VERSION ""

NS_ :

BS_:

BU_: TPMS
VAL_TABLE_ FMI 31 "ConditionExists" 19 "Received network data in error" 18 "Below normal (moderately severe)" 17 "Below normal (least severe)" 16 "Above normal (moderately severe)" 15 "Above normal (least severe)" 14 "Special intstructions" 13 "Out of calibration" 12 "Bad intelligent device" 11 "Root cause not known" 10 "Abnormal rate of change" 9 "Abnormal update rate" 8 "Abnormal frequency" 7 "Mechanical system not responding" 6 "Current above normal" 5 "Current below normal" 4 "Voltage below normal" 3 "Voltage above normal" 2 "Data erratic" 1 "Below normal (most severe)" 0 "Above normal (most severe)" ;

BO_ 2566838526 CA: 9 Vector__XXX
 SG_ ArbitraryAddressCapable : 63|1@1+ (1,0) [0|1] "" Vector__XXX
 SG_ IndustryGroup : 60|3@1+ (1,0) [0|7] "" Vector__XXX
 SG_ VehicleSystemInstance : 56|4@1+ (1,0) [0|15] "" Vector__XXX
 SG_ VehicleSystem : 49|7@1+ (1,0) [0|127] "" Vector__XXX
 SG_ Function : 40|8@1+ (1,0) [0|255] "" Vector__XXX
 SG_ FunctionInstance : 35|5@1+ (1,0) [0|31] "" Vector__XXX
 SG_ ECUInstance : 32|3@1+ (1,0) [0|7] "" Vector__XXX
 SG_ ManufacturerCode : 21|11@1+ (1,0) [0|2047] "" Vector__XXX
 SG_ IdentityNumber : 0|21@1+ (1,0) [0|2097152] "" Vector__XXX
 SG_ AddressAssignment : 64|8@1+ (1,0) [0|255] "" Vector__XXX

BO_ 2561605374 TPRS: 8 Vector__XXX
 SG_ ReferenceTirePressSetting : 8|8@1+ (8,0) [0|2000] "kPa" Vector__XXX
 SG_ TireLocation : 0|8@1+ (1,0) [0|255] "" Vector__XXX

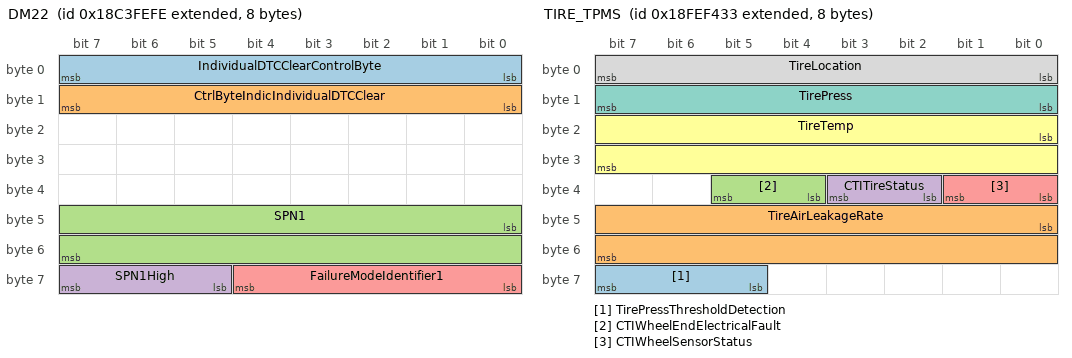
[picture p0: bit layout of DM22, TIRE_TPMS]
BO_ 2562981630 DM22: 8 Vector__XXX
 SG_ IndividualDTCClearControlByte : 0|8@1+ (1,0) [0|255] "" Vector__XXX
 SG_ CtrlByteIndicIndividualDTCClear : 8|8@1+ (1,0) [0|255] "" Vector__XXX
 SG_ SPN1 : 40|16@1+ (1,0) [0|65536] "" Vector__XXX
 SG_ SPN1High : 61|3@1+ (1,0) [0|7] "" Vector__XXX
 SG_ FailureModeIdentifier1 : 56|5@1+ (1,0) [0|0] "" Vector__XXX

BO_ 2684354558 CAPL_MSG: 1785 Vector__XXX

BO_ 2566764851 TPRI_TPMS: 8 TPMS
 SG_ ReferenceTirePress : 8|8@1+ (8,0) [0|2000] "kPa" Vector__XXX
 SG_ TireLocation : 0|8@1+ (1,0) [0|255] "" Vector__XXX

BO_ 2566845491 TIRE_TPMS: 8 TPMS
 SG_ TirePressThresholdDetection : 61|3@1+ (1,0) [0|7] "" Vector__XXX
 SG_ TireAirLeakageRate : 40|16@1+ (0.1,0) [0|6425.5] "Pa/s" Vector__XXX
 SG_ CTIWheelEndElectricalFault : 36|2@1+ (1,0) [0|3] "" Vector__XXX
 SG_ CTITireStatus : 34|2@1+ (1,0) [0|3] "" Vector__XXX
 SG_ CTIWheelSensorStatus : 32|2@1+ (1,0) [0|3] "" Vector__XXX
 SG_ TireTemp : 16|16@1+ (0.03125,-273) [-273|1735] "deg" Vector__XXX
 SG_ TirePress : 8|8@1+ (4,0) [0|1000] "kPa" Vector__XXX
 SG_ TireLocation : 0|8@1+ (1,0) [0|255] "" Vector__XXX

BO_ 2566839038 SOFT: 8 TPMS
 SG_ NmbrOfSftwrIdentificationFields : 0|8@1+ (1,0) [0|250] "steps" Vector__XXX

BO_ 2566768126 ECUID: 8 TPMS

BO_ 2566836222 DM6: 22 Vector__XXX
 SG_ SPN5 : 144|16@1+ (1,0) [0|65536] "" Vector__XXX
 SG_ SPN4 : 112|16@1+ (1,0) [0|65536] "" Vector__XXX
 SG_ SPN3 : 80|16@1+ (1,0) [0|65536] "" Vector__XXX
 SG_ SPN2 : 48|16@1+ (1,0) [0|65536] "" Vector__XXX
 SG_ FailureModeIdentifier5 : 160|5@1+ (1,0) [0|0] "" Vector__XXX
 SG_ FailureModeIdentifier4 : 128|5@1+ (1,0) [0|0] "" Vector__XXX
 SG_ FlashRedStopLamp : 12|2@1+ (1,0) [0|3] "" Vector__XXX
 SG_ FlashProtectLamp : 8|2@1+ (1,0) [0|3] "" Vector__XXX
 SG_ FlashMalfuncIndicatorLamp : 14|2@1+ (1,0) [0|3] "" Vector__XXX
 SG_ FlashAmberWarningLamp : 10|2@1+ (1,0) [0|3] "" Vector__XXX
 SG_ FailureModeIdentifier3 : 96|5@1+ (1,0) [0|0] "" Vector__XXX
 SG_ FailureModeIdentifier2 : 64|5@1+ (1,0) [0|0] "" Vector__XXX
 SG_ SPNConversionMethod5 : 175|1@1+ (1,0) [0|1] "" Vector__XXX
 SG_ SPNConversionMethod4 : 143|1@1+ (1,0) [0|1] "" Vector__XXX
 SG_ SPNConversionMethod3 : 111|1@1+ (1,0) [0|1] "" Vector__XXX
 SG_ SPNConversionMethod2 : 79|1@1+ (1,0) [0|1] "" Vector__XXX
 SG_ OccurenceCount5 : 168|7@1+ (1,0) [0|126] "" Vector__XXX
 SG_ OccurenceCount4 : 136|7@1+ (1,0) [0|126] "" Vector__XXX
 SG_ OccurenceCount3 : 104|7@1+ (1,0) [0|126] "" Vector__XXX
 SG_ OccurenceCount2 : 72|7@1+ (1,0) [0|126] "" Vector__XXX
 SG_ OccurenceCount1 : 40|7@1+ (1,0) [0|126] "" Vector__XXX
 SG_ SPNConversionMethod1 : 47|1@1+ (1,0) [0|1] "" Vector__XXX
 SG_ FailureModeIdentifier1 : 32|5@1+ (1,0) [0|0] "" Vector__XXX
 SG_ SPN1 : 16|16@1+ (1,0) [0|65536] "" Vector__XXX
 SG_ MalfunctionIndicatorLampStatus : 6|2@1+ (1,0) [0|3] "" Vector__XXX
 SG_ RedStopLampState : 4|2@1+ (1,0) [0|3] "" Vector__XXX
 SG_ AmberWarningLampStatus : 2|2@1+ (1,0) [0|3] "" Vector__XXX
 SG_ ProtectLampStatus : 0|2@1+ (1,0) [0|3] "" Vector__XXX
 SG_ SPN5High : 165|3@1+ (1,0) [0|7] "" Vector__XXX
 SG_ SPN4High : 133|3@1+ (1,0) [0|7] "" Vector__XXX
 SG_ SPN3High : 101|3@1+ (1,0) [0|7] "" Vector__XXX
 SG_ SPN2High : 69|3@1+ (1,0) [0|7] "" Vector__XXX
 SG_ SPN1High : 37|3@1+ (1,0) [0|7] "" Vector__XXX

BO_ 2566835966 DM5: 8 TPMS
 SG_ MisfireMonitoringSupport : 24|1@1+ (1,0) [0|0] "" Vector__XXX
 SG_ OBDCompliance : 16|8@1+ (1,0) [0|240] "" Vector__XXX
 SG_ PreviouslyActiveTroubleCodes : 8|8@1+ (1,0) [0|240] "" Vector__XXX
 SG_ ActiveTroubleCodes : 0|8@1+ (1,0) [0|240] "" Vector__XXX
 SG_ SecondAirSystemMonStatus : 51|1@1+ (1,0) [0|1] "" Vector__XXX
 SG_ EvaporativeSystemMonStatus : 50|1@1+ (1,0) [0|1] "" Vector__XXX
 SG_ ACSystemRefrigerantMonStatus : 52|1@1+ (1,0) [0|1] "" Vector__XXX
 SG_ OxygenSensorHeaterMonStatus : 54|1@1+ (1,0) [0|1] "" Vector__XXX
 SG_ OxygenSensorMonStatus : 53|1@1+ (1,0) [0|1] "" Vector__XXX
 SG_ EGRSystemMonitoringStatus : 55|1@1+ (1,0) [0|1] "" Vector__XXX
 SG_ CatalystMonStatus : 48|1@1+ (1,0) [0|1] "" Vector__XXX
 SG_ ColdStartAidSystemMonStatus : 56|1@1+ (1,0) [0|1] "" Vector__XXX
 SG_ HeatedCatalystMonStatus : 49|1@1+ (1,0) [0|0] "" Vector__XXX
 SG_ CatalystMonSupp : 32|1@1+ (1,0) [0|1] "" Vector__XXX
 SG_ ColdStartAidSystemMonSupp : 40|1@1+ (1,0) [0|1] "" Vector__XXX
 SG_ HeatedCatalystMonSupp : 33|1@1+ (1,0) [0|0] "" Vector__XXX
 SG_ EvaporativeSystemMonSupp : 34|1@1+ (1,0) [0|1] "" Vector__XXX
 SG_ SecondAirSystemMonSupp : 35|1@1+ (1,0) [0|1] "" Vector__XXX
 SG_ ACSystemRefrigerantMonSupp : 36|1@1+ (1,0) [0|1] "" Vector__XXX
 SG_ OxygenSensorMonSupp : 37|1@1+ (1,0) [0|1] "" Vector__XXX
 SG_ OxygenSensorHeaterMonSupp : 38|1@1+ (1,0) [0|1] "" Vector__XXX
 SG_ EGRSystemMonitoringSupp : 39|1@1+ (1,0) [0|1] "" Vector__XXX
 SG_ MisfireMonitoringStatus : 28|1@1+ (1,0) [0|0] "" Vector__XXX
 SG_ ComprehensiveCompMonStatus : 30|1@1+ (1,0) [0|1] "" Vector__XXX
 SG_ FuelSystemMonitoringStatus : 29|1@1+ (1,0) [0|1] "" Vector__XXX
 SG_ ComprehensiveComponentMonSupp : 26|1@1+ (1,0) [0|0] "" Vector__XXX
 SG_ FuelSystemMonitoringSupport : 25|1@1+ (1,0) [0|1] "" Vector__XXX

BO_ 2566835710 DM4: 13 TPMS
 SG_ OccurenceCount1 : 32|7@1+ (1,0) [0|126] "" Vector__XXX
 SG_ SPNConversionMethod1 : 39|1@1+ (1,0) [0|1] "" Vector__XXX
 SG_ FailureModeIdentifier1 : 24|5@1+ (1,0) [0|0] "" Vector__XXX
 SG_ SPN1 : 8|16@1+ (1,0) [0|65536] "" Vector__XXX
 SG_ FreezeFrameLength : 0|8@1+ (1,0) [0|255] "byte" Vector__XXX
 SG_ EngSpeed : 56|16@1+ (0.125,0) [0|8031.875] "rpm" Vector__XXX
 SG_ EngTorqueMode : 40|4@1+ (1,0) [0|15] "" Vector__XXX
 SG_ EngTurboBoostPress : 48|8@1+ (2,0) [0|500] "kPa" Vector__XXX
 SG_ WheelBasedVehicleSpeed : 88|16@1+ (0.00390625,0) [0|250.996] "km/h" Vector__XXX
 SG_ EngPercentLoadAtCurrentSpeed : 72|8@1+ (1,0) [0|250] "%" Vector__XXX
 SG_ EngineCoolantTemperature : 80|8@1+ (1,-40) [-40|210] "°C" Vector__XXX
 SG_ SPN1High : 29|3@1+ (1,0) [0|7] "" Vector__XXX

BO_ 2566835454 DM3: 0 Vector__XXX

BO_ 2566764542 DM25: 13 TPMS
 SG_ OccurenceCount1 : 32|7@1+ (1,0) [0|126] "" Vector__XXX
 SG_ SPNConversionMethod1 : 39|1@1+ (1,0) [0|1] "" Vector__XXX
 SG_ FailureModeIdentifier1 : 24|5@1+ (1,0) [0|0] "" Vector__XXX
 SG_ SPN1 : 8|16@1+ (1,0) [0|65536] "" Vector__XXX
 SG_ ExpandedFreezeFrameLength : 0|8@1+ (1,0) [0|255] "byte" Vector__XXX
 SG_ SPN1High : 29|3@1+ (1,0) [0|7] "" Vector__XXX

BO_ 2566764286 DM24: 12 TPMS
 SG_ SPNSupported1High : 21|3@1+ (1,0) [0|7] "" Vector__XXX
 SG_ SPNSupportTypeSTR3 : 82|1@1+ (1,0) [0|1] "" Vector__XXX
 SG_ SPNSupportTypeSTR2 : 50|1@1+ (1,0) [0|1] "" Vector__XXX
 SG_ SPNSupportTypeEFF3 : 80|1@1+ (1,0) [0|1] "" Vector__XXX
 SG_ SPNSupportTypeEFF2 : 48|1@1+ (1,0) [0|1] "" Vector__XXX
 SG_ SPNSupportTypeDS3 : 81|1@1+ (1,0) [0|1] "" Vector__XXX
 SG_ SPNSupportTypeDS2 : 49|1@1+ (1,0) [0|1] "" Vector__XXX
 SG_ SPNSupported3High : 85|3@1+ (1,0) [0|7] "" Vector__XXX
 SG_ SPNSupported2High : 53|3@1+ (1,0) [0|7] "" Vector__XXX
 SG_ SPNSupported3 : 64|16@1+ (1,0) [0|65535] "" Vector__XXX
 SG_ SPNSupported2 : 32|16@1+ (1,0) [0|65535] "" Vector__XXX
 SG_ SPNDataLength3 : 88|8@1+ (1,0) [0|240] "" Vector__XXX
 SG_ SPNSupportTypeSTR1 : 18|1@1+ (1,0) [0|1] "" Vector__XXX
 SG_ SPNSupportTypeDS1 : 17|1@1+ (1,0) [0|1] "" Vector__XXX
 SG_ SPNSupportTypeEFF1 : 16|1@1+ (1,0) [0|1] "" Vector__XXX
 SG_ SPNDataLength2 : 56|8@1+ (1,0) [0|240] "" Vector__XXX
 SG_ SPNDataLength1 : 24|8@1+ (1,0) [0|240] "" Vector__XXX
 SG_ SPNSupported1 : 0|16@1+ (1,0) [0|65535] "" Vector__XXX

BO_ 2566835198 DM2: 22 TPMS
 SG_ SPN5 : 144|16@1+ (1,0) [0|65536] "" Vector__XXX
 SG_ SPN4 : 112|16@1+ (1,0) [0|65536] "" Vector__XXX
 SG_ SPN3 : 80|16@1+ (1,0) [0|65536] "" Vector__XXX
 SG_ SPN2 : 48|16@1+ (1,0) [0|65536] "" Vector__XXX
 SG_ FailureModeIdentifier5 : 160|5@1+ (1,0) [0|0] "" Vector__XXX
 SG_ FailureModeIdentifier4 : 128|5@1+ (1,0) [0|0] "" Vector__XXX
 SG_ OccurenceCount1 : 40|7@1+ (1,0) [0|126] "" Vector__XXX
 SG_ SPNConversionMethod1 : 47|1@1+ (1,0) [0|1] "" Vector__XXX
 SG_ FailureModeIdentifier1 : 32|5@1+ (1,0) [0|0] "" Vector__XXX
 SG_ SPN1 : 16|16@1+ (1,0) [0|65536] "" Vector__XXX
 SG_ MalfunctionIndicatorLampStatus : 6|2@1+ (1,0) [0|3] "" Vector__XXX
 SG_ RedStopLampState : 4|2@1+ (1,0) [0|3] "" Vector__XXX
 SG_ AmberWarningLampStatus : 2|2@1+ (1,0) [0|3] "" Vector__XXX
 SG_ ProtectLampStatus : 0|2@1+ (1,0) [0|3] "" Vector__XXX
 SG_ FailureModeIdentifier3 : 96|5@1+ (1,0) [0|0] "" Vector__XXX
 SG_ FlashRedStopLamp : 12|2@1+ (1,0) [0|3] "" Vector__XXX
 SG_ FlashProtectLamp : 8|2@1+ (1,0) [0|3] "" Vector__XXX
 SG_ FlashMalfuncIndicatorLamp : 14|2@1+ (1,0) [0|3] "" Vector__XXX
 SG_ FlashAmberWarningLamp : 10|2@1+ (1,0) [0|3] "" Vector__XXX
 SG_ FailureModeIdentifier2 : 64|5@1+ (1,0) [0|0] "" Vector__XXX
 SG_ SPNConversionMethod5 : 175|1@1+ (1,0) [0|1] "" Vector__XXX
 SG_ SPNConversionMethod4 : 143|1@1+ (1,0) [0|1] "" Vector__XXX
 SG_ SPNConversionMethod3 : 111|1@1+ (1,0) [0|1] "" Vector__XXX
 SG_ SPNConversionMethod2 : 79|1@1+ (1,0) [0|1] "" Vector__XXX
 SG_ OccurenceCount5 : 168|7@1+ (1,0) [0|126] "" Vector__XXX
 SG_ OccurenceCount4 : 136|7@1+ (1,0) [0|126] "" Vector__XXX
 SG_ OccurenceCount3 : 104|7@1+ (1,0) [0|126] "" Vector__XXX
 SG_ OccurenceCount2 : 72|7@1+ (1,0) [0|126] "" Vector__XXX
 SG_ SPN5High : 165|3@1+ (1,0) [0|7] "" Vector__XXX
 SG_ SPN4High : 133|3@1+ (1,0) [0|7] "" Vector__XXX
 SG_ SPN3High : 101|3@1+ (1,0) [0|7] "" Vector__XXX
 SG_ SPN2High : 69|3@1+ (1,0) [0|7] "" Vector__XXX
 SG_ SPN1High : 37|3@1+ (1,0) [0|7] "" Vector__XXX

BO_ 2564030206 DM19: 20 Vector__XXX
 SG_ CalibrationID4 : 128|32@1+ (1,0) [0|4294967295] "" Vector__XXX
 SG_ CalibrationID3 : 96|32@1+ (1,0) [0|4294967295] "" Vector__XXX
 SG_ CalibrationID2 : 64|32@1+ (1,0) [0|4294967295] "" Vector__XXX
 SG_ CalibrationID1 : 32|32@1+ (1,0) [0|4294967295] "" Vector__XXX
 SG_ CalibrationVerificationNumber : 0|32@1+ (1,0) [0|4294967295] "" Vector__XXX

BO_ 2566837502 DM12: 22 Vector__XXX
 SG_ SPN5 : 144|16@1+ (1,0) [0|65536] "" Vector__XXX
 SG_ SPN4 : 112|16@1+ (1,0) [0|65536] "" Vector__XXX
 SG_ SPN3 : 80|16@1+ (1,0) [0|65536] "" Vector__XXX
 SG_ SPN2 : 48|16@1+ (1,0) [0|65536] "" Vector__XXX
 SG_ FlashRedStopLamp : 12|2@1+ (1,0) [0|3] "" Vector__XXX
 SG_ FlashProtectLamp : 8|2@1+ (1,0) [0|3] "" Vector__XXX
 SG_ FailureModeIdentifier5 : 160|5@1+ (1,0) [0|0] "" Vector__XXX
 SG_ FailureModeIdentifier4 : 128|5@1+ (1,0) [0|0] "" Vector__XXX
 SG_ FailureModeIdentifier3 : 96|5@1+ (1,0) [0|0] "" Vector__XXX
 SG_ OccurenceCount1 : 40|7@1+ (1,0) [0|126] "" Vector__XXX
 SG_ SPNConversionMethod1 : 47|1@1+ (1,0) [0|1] "" Vector__XXX
 SG_ FailureModeIdentifier1 : 32|5@1+ (1,0) [0|0] "" Vector__XXX
 SG_ SPN1 : 16|16@1+ (1,0) [0|65536] "" Vector__XXX
 SG_ MalfunctionIndicatorLampStatus : 6|2@1+ (1,0) [0|3] "" Vector__XXX
 SG_ RedStopLampState : 4|2@1+ (1,0) [0|3] "" Vector__XXX
 SG_ AmberWarningLampStatus : 2|2@1+ (1,0) [0|3] "" Vector__XXX
 SG_ ProtectLampStatus : 0|2@1+ (1,0) [0|3] "" Vector__XXX
 SG_ FlashMalfuncIndicatorLamp : 14|2@1+ (1,0) [0|3] "" Vector__XXX
 SG_ FlashAmberWarningLamp : 10|2@1+ (1,0) [0|3] "" Vector__XXX
 SG_ FailureModeIdentifier2 : 64|5@1+ (1,0) [0|0] "" Vector__XXX
 SG_ SPNConversionMethod5 : 175|1@1+ (1,0) [0|1] "" Vector__XXX
 SG_ SPNConversionMethod4 : 143|1@1+ (1,0) [0|1] "" Vector__XXX
 SG_ SPNConversionMethod3 : 111|1@1+ (1,0) [0|1] "" Vector__XXX
 SG_ SPNConversionMethod2 : 79|1@1+ (1,0) [0|1] "" Vector__XXX
 SG_ OccurenceCount5 : 168|7@1+ (1,0) [0|126] "" Vector__XXX
 SG_ OccurenceCount4 : 136|7@1+ (1,0) [0|126] "" Vector__XXX
 SG_ OccurenceCount3 : 104|7@1+ (1,0) [0|126] "" Vector__XXX
 SG_ OccurenceCount2 : 72|7@1+ (1,0) [0|126] "" Vector__XXX
 SG_ SPN5High : 165|3@1+ (1,0) [0|7] "" Vector__XXX
 SG_ SPN4High : 133|3@1+ (1,0) [0|7] "" Vector__XXX
 SG_ SPN3High : 101|3@1+ (1,0) [0|7] "" Vector__XXX
 SG_ SPN2High : 69|3@1+ (1,0) [0|7] "" Vector__XXX
 SG_ SPN1High : 37|3@1+ (1,0) [0|7] "" Vector__XXX

BO_ 2566834942 DM1: 22 TPMS
 SG_ SPN5 : 144|16@1+ (1,0) [0|65536] "" Vector__XXX
 SG_ SPN4 : 112|16@1+ (1,0) [0|65536] "" Vector__XXX
 SG_ SPN3 : 80|16@1+ (1,0) [0|65536] "" Vector__XXX
 SG_ SPN2 : 48|16@1+ (1,0) [0|65536] "" Vector__XXX
 SG_ FailureModeIdentifier5 : 160|5@1+ (1,0) [0|0] "" Vector__XXX
 SG_ FailureModeIdentifier4 : 128|5@1+ (1,0) [0|0] "" Vector__XXX
 SG_ FailureModeIdentifier3 : 96|5@1+ (1,0) [0|0] "" Vector__XXX
 SG_ FlashRedStopLamp : 12|2@1+ (1,0) [0|3] "" Vector__XXX
 SG_ FlashProtectLamp : 8|2@1+ (1,0) [0|3] "" Vector__XXX
 SG_ FlashMalfuncIndicatorLamp : 14|2@1+ (1,0) [0|3] "" Vector__XXX
 SG_ FlashAmberWarningLamp : 10|2@1+ (1,0) [0|3] "" Vector__XXX
 SG_ MalfunctionIndicatorLampStatus : 6|2@1+ (1,0) [0|3] "" Vector__XXX
 SG_ AmberWarningLampStatus : 2|2@1+ (1,0) [0|3] "" Vector__XXX
 SG_ OccurenceCount1 : 40|7@1+ (1,0) [0|126] "" Vector__XXX
 SG_ SPNConversionMethod1 : 47|1@1+ (1,0) [0|1] "" Vector__XXX
 SG_ FailureModeIdentifier1 : 32|5@1+ (1,0) [0|0] "" Vector__XXX
 SG_ SPN1 : 16|16@1+ (1,0) [0|65536] "" Vector__XXX
 SG_ RedStopLampState : 4|2@1+ (1,0) [0|3] "" Vector__XXX
 SG_ ProtectLampStatus : 0|2@1+ (1,0) [0|3] "" Vector__XXX
 SG_ FailureModeIdentifier2 : 64|5@1+ (1,0) [0|0] "" Vector__XXX
 SG_ SPNConversionMethod5 : 175|1@1+ (1,0) [0|1] "" Vector__XXX
 SG_ SPNConversionMethod4 : 143|1@1+ (1,0) [0|1] "" Vector__XXX
 SG_ SPNConversionMethod3 : 111|1@1+ (1,0) [0|1] "" Vector__XXX
 SG_ SPNConversionMethod2 : 79|1@1+ (1,0) [0|1] "" Vector__XXX
 SG_ OccurenceCount5 : 168|7@1+ (1,0) [0|126] "" Vector__XXX
 SG_ OccurenceCount4 : 136|7@1+ (1,0) [0|126] "" Vector__XXX
 SG_ OccurenceCount3 : 104|7@1+ (1,0) [0|126] "" Vector__XXX
 SG_ OccurenceCount2 : 72|7@1+ (1,0) [0|126] "" Vector__XXX
 SG_ SPN5High : 165|3@1+ (1,0) [0|7] "" Vector__XXX
 SG_ SPN4High : 133|3@1+ (1,0) [0|7] "" Vector__XXX
 SG_ SPN3High : 101|3@1+ (1,0) [0|7] "" Vector__XXX
 SG_ SPN2High : 69|3@1+ (1,0) [0|7] "" Vector__XXX
 SG_ SPN1High : 37|3@1+ (1,0) [0|7] "" Vector__XXX

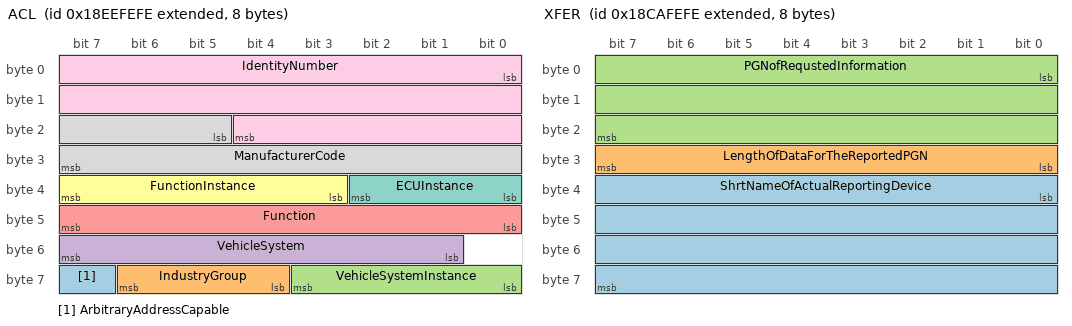
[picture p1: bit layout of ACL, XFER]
BO_ 2565799678 ACL: 8 TPMS
 SG_ ArbitraryAddressCapable : 63|1@1+ (1,0) [0|1] "" Vector__XXX
 SG_ IndustryGroup : 60|3@1+ (1,0) [0|7] "" Vector__XXX
 SG_ VehicleSystemInstance : 56|4@1+ (1,0) [0|15] "" Vector__XXX
 SG_ VehicleSystem : 49|7@1+ (1,0) [0|127] "" Vector__XXX
 SG_ Function : 40|8@1+ (1,0) [0|255] "" Vector__XXX
 SG_ FunctionInstance : 35|5@1+ (1,0) [0|31] "" Vector__XXX
 SG_ ECUInstance : 32|3@1+ (1,0) [0|7] "" Vector__XXX
 SG_ ManufacturerCode : 21|11@1+ (1,0) [0|2047] "" Vector__XXX
 SG_ IdentityNumber : 0|21@1+ (1,0) [0|2097152] "" Vector__XXX

BO_ 2563440382 XFER: 8 Vector__XXX
 SG_ ShrtNameOfActualReportingDevice : 32|32@1+ (1,0) [0|0] "(2^32 - 1)" Vector__XXX
 SG_ LengthOfDataForTheReportedPGN : 24|8@1+ (1,0) [0|255] "" Vector__XXX
 SG_ PGNofRequstedInformation : 0|24@1+ (1,0) [0|16777215] "" Vector__XXX

BO_ 2565603070 TPDT: 8 Vector__XXX
 SG_ SequenceNumber : 0|8@1+ (1,0) [0|252] "" Vector__XXX

BO_ 2565668606 TPCM: 8 Vector__XXX
 SG_ TotalNumberOfPacketsEoMA m19 : 24|8@1+ (1,0) [0|255] "" Vector__XXX
 SG_ TotalMessageSizeEoMA m19 : 8|16@1+ (1,0) [0|64255] "counts" Vector__XXX
 SG_ TotalMessageSizeBAM m32 : 8|16@1+ (1,0) [0|64255] "counts" Vector__XXX
 SG_ TotalNumberOfPacketsBAM m32 : 24|8@1+ (1,0) [0|255] "" Vector__XXX
 SG_ ConnectionAbortReason m255 : 8|8@1+ (1,0) [0|255] "" Vector__XXX
 SG_ NextPacketNumberToBeSent m17 : 16|8@1+ (1,0) [0|255] "" Vector__XXX
 SG_ NumberOfPacketsThatCanBeSent m17 : 8|8@1+ (1,0) [0|255] "" Vector__XXX
 SG_ PGNumber : 40|24@1+ (1,0) [0|16777200] "" Vector__XXX
 SG_ MaximumNumberOfPackets m16 : 32|8@1+ (1,0) [0|255] "" Vector__XXX
 SG_ TotalNumberOfPackets m16 : 24|8@1+ (1,0) [0|255] "" Vector__XXX
 SG_ TotalMessageSize m16 : 8|16@1+ (1,0) [0|64255] "counts" Vector__XXX
 SG_ ControlByte M : 0|8@1+ (1,0) [0|255] "" Vector__XXX

BO_ 2563374846 RQST2: 8 Vector__XXX
 SG_ UseTransferMode : 24|2@1+ (1,0) [0|3] "" Vector__XXX
 SG_ ParameterGroupNumber : 0|24@1+ (1,0) [0|16777215] "" Vector__XXX

BO_ 2565537534 RQST: 3 Vector__XXX
 SG_ ParameterGroupNumber : 0|24@1+ (1,0) [0|16777215] "" Vector__XXX

BO_ 2565406462 ACKM: 8 TPMS
 SG_ AddressBusy m3 : 32|8@1+ (1,0) [0|255] "" Vector__XXX
 SG_ ParameterGroupNumber : 40|24@1+ (1,0) [0|16777215] "" Vector__XXX
 SG_ GroupFunctionValue : 8|8@1+ (1,0) [0|255] "" Vector__XXX
 SG_ ControlByte M : 0|8@1+ (1,0) [0|255] "" Vector__XXX
 SG_ AddressAccessDenied m2 : 32|8@1+ (1,0) [0|255] "" Vector__XXX
 SG_ AddressNegativeAcknowledgement m1 : 32|8@1+ (1,0) [0|255] "" Vector__XXX
 SG_ AddressAcknowledged m0 : 32|8@1+ (1,0) [0|255] "" Vector__XXX

EV_ EnvIgnitionSwitch: 0 [0|2] "" 2 1 DUMMY_NODE_VECTOR0 Vector__XXX;

EV_ EnvTPMS_Recalibrate: 0 [0|1] "" 0 2 DUMMY_NODE_VECTOR0 Vector__XXX;

EV_ EnvTPMS_Rear2RightWheelBitmap: 0 [0|3] "" 0 3 DUMMY_NODE_VECTOR0 Vector__XXX;

EV_ EnvTPMS_Rear2RightState: 0 [0|5] "" 0 4 DUMMY_NODE_VECTOR0 Vector__XXX;

EV_ EnvTPMS_Rear2RightPressure: 1 [0|1000] "kPa" 800 5 DUMMY_NODE_VECTOR0 Vector__XXX;

EV_ EnvTPMS_Rear2LeftWheelBitmap: 0 [0|3] "" 0 6 DUMMY_NODE_VECTOR0 Vector__XXX;

EV_ EnvTPMS_Rear2LeftState: 0 [0|5] "" 0 7 DUMMY_NODE_VECTOR0 Vector__XXX;

EV_ EnvTPMS_Rear2LeftPressure: 1 [0|1000] "kPa" 800 8 DUMMY_NODE_VECTOR0 Vector__XXX;

EV_ EnvTPMS_Rear1RightWheelBitmap: 0 [0|3] "" 0 9 DUMMY_NODE_VECTOR0 Vector__XXX;

EV_ EnvTPMS_Rear1RightState: 0 [0|5] "" 0 10 DUMMY_NODE_VECTOR0 Vector__XXX;

EV_ EnvTPMS_Rear1RightPressure: 1 [0|1000] "kPa" 800 11 DUMMY_NODE_VECTOR0 Vector__XXX;

EV_ EnvTPMS_Rear1LeftWheelBitmap: 0 [0|3] "" 0 12 DUMMY_NODE_VECTOR0 Vector__XXX;

EV_ EnvTPMS_Rear1LeftState: 0 [0|5] "" 0 13 DUMMY_NODE_VECTOR0 Vector__XXX;

EV_ EnvTPMS_Rear1LeftPressure: 1 [0|1000] "kPa" 800 14 DUMMY_NODE_VECTOR0 Vector__XXX;

EV_ EnvTPMS_FrontRightWheelBitmap: 0 [0|3] "" 0 15 DUMMY_NODE_VECTOR0 Vector__XXX;

EV_ EnvTPMS_FrontRightState: 0 [0|5] "" 0 16 DUMMY_NODE_VECTOR0 Vector__XXX;

EV_ EnvTPMS_FrontRightPressure: 1 [0|1000] "kPa" 728 17 DUMMY_NODE_VECTOR0 Vector__XXX;

EV_ EnvTPMS_FrontLeftWheelBitmap: 0 [0|3] "" 0 18 DUMMY_NODE_VECTOR0 Vector__XXX;

EV_ EnvTPMS_FrontLeftState: 0 [0|5] "" 0 19 DUMMY_NODE_VECTOR0 Vector__XXX;

EV_ EnvTPMS_FrontLeftPressure: 1 [0|1000] "kPa" 728 20 DUMMY_NODE_VECTOR0 Vector__XXX;

CM_ BU_ TPMS "Tire Pressure Monitoring System";
CM_ BO_ 2566838526 "Commanded Address";
CM_ SG_ 2566838526 IndustryGroup "0 = Global; 
   1  = On-Highway; 
   2  = Agricultural and Forestry; 
   3  = Construction; 
   4  = Marine;
   5  = Industrial - Process
          Control - Stationary (Gen-Sets)
   6  = Reserve for SAE
   7  = Reserve for SAE";
CM_ SG_ 2566838526 ManufacturerCode "Assigned by NMEA 2000 Committee";
CM_ SG_ 2566838526 AddressAssignment "The source address that is to be assigned to the CA that has the NAME corresponding to the one conveyed in the first eight bytes of this Commanded Address message.";
CM_ BO_ 2561605374 "Tire Pressure Reference Setting";
CM_ SG_ 2561605374 TireLocation "Identifies which tire is associated with the parametric data in this PGN.";
CM_ BO_ 2562981630 "Individual Clear/Reset of active and previously active DTC.";
CM_ SG_ 2562981630 SPN1 "SPN #1 (Conversion Version 4)";
CM_ SG_ 2562981630 SPN1High "SPN #1 (Conversion Version 4)";
CM_ SG_ 2562981630 FailureModeIdentifier1 "The FMI defines the type of failure detected in the subsystem identified by an SPN.";
CM_ BO_ 2566764851 "Tire Pressure Reference Information";
CM_ SG_ 2566764851 TireLocation "Identifies which tire is associated with the parametric data in this PGN.";
CM_ BO_ 2566845491 "Tire Condition";
CM_ SG_ 2566845491 TirePressThresholdDetection "Signal indicating the pressure level of the tire.";
CM_ SG_ 2566845491 TireAirLeakageRate "The pressure loss rate of a tire.";
CM_ SG_ 2566845491 CTIWheelEndElectricalFault "Indicates the status of electrical fault on CTI wheel interface.";
CM_ SG_ 2566845491 CTITireStatus "Indicates the status of the tire.";
CM_ SG_ 2566845491 CTIWheelSensorStatus "Indicates whether the wheel is being monitored by the CTI controller.";
CM_ SG_ 2566845491 TireTemp "Temperature at the surface of the tire sidewall.";
CM_ SG_ 2566845491 TirePress "Pressure at which air is contained in cavity formed by tire and rim.";
CM_ SG_ 2566845491 TireLocation "Identifies which tire is associated with the parametric data in this PGN.";
CM_ BO_ 2566839038 "Software Identification";
CM_ SG_ 2566839038 NmbrOfSftwrIdentificationFields "Number of software identification designators represented in the software identification parameter group.";
CM_ BO_ 2566768126 "ECU Identification Information";
CM_ BO_ 2566836222 "Pending DTCs";
CM_ SG_ 2566836222 SPN5 "SPN #5 (Conversion Version 4)";
CM_ SG_ 2566836222 SPN4 "SPN #4 (Conversion Version 4)";
CM_ SG_ 2566836222 SPN3 "SPN #3 (Conversion Version 4)";
CM_ SG_ 2566836222 SPN2 "SPN #2 (Conversion Version 4)";
CM_ SG_ 2566836222 FailureModeIdentifier5 "The FMI defines the type of failure detected in the subsystem identified by an SPN.";
CM_ SG_ 2566836222 FailureModeIdentifier4 "The FMI defines the type of failure detected in the subsystem identified by an SPN.";
CM_ SG_ 2566836222 FlashRedStopLamp "This parameter provides the capability to flash the RSL (SPN 3039).";
CM_ SG_ 2566836222 FlashProtectLamp "This parameter provides the capability to flash the engine protect lamp (SPN 3041).";
CM_ SG_ 2566836222 FlashMalfuncIndicatorLamp "This parameter provides the capability to flash the MIL (SPN 3038).";
CM_ SG_ 2566836222 FlashAmberWarningLamp "This parameter provides the capability to flash the AWL (SPN 3040). ";
CM_ SG_ 2566836222 FailureModeIdentifier3 "The FMI defines the type of failure detected in the subsystem identified by an SPN.";
CM_ SG_ 2566836222 FailureModeIdentifier2 "The FMI defines the type of failure detected in the subsystem identified by an SPN.";
CM_ SG_ 2566836222 OccurenceCount5 "The 7 bit occurence count field contains the number of times a fault has gone from active to previously active.";
CM_ SG_ 2566836222 OccurenceCount4 "The 7 bit occurence count field contains the number of times a fault has gone from active to previously active.";
CM_ SG_ 2566836222 OccurenceCount3 "The 7 bit occurence count field contains the number of times a fault has gone from active to previously active.";
CM_ SG_ 2566836222 OccurenceCount2 "The 7 bit occurence count field contains the number of times a fault has gone from active to previously active.";
CM_ SG_ 2566836222 OccurenceCount1 "The 7 bit occurence count field contains the number of times a fault has gone from active to previously active.";
CM_ SG_ 2566836222 FailureModeIdentifier1 "The FMI defines the type of failure detected in the subsystem identified by an SPN.";
CM_ SG_ 2566836222 SPN1 "SPN #1 (Conversion Version 4)";
CM_ SG_ 2566836222 MalfunctionIndicatorLampStatus "A lamp used to relay only emissions-related trouble code information.";
CM_ SG_ 2566836222 RedStopLampState "This lamp is uesed to relay trouble code information that is of a severe enought condition that it warrants stopping the vehicle.";
CM_ SG_ 2566836222 AmberWarningLampStatus "This lamp is used to relay trouble code information that is reporting a problem with the vehicle system but the vehicle need
not be immediately stopped.";
CM_ SG_ 2566836222 ProtectLampStatus "This lamp is used to relay trouble code informatio that is reporting a problem with a vehicle system that is most
probably not electronic subsystem related.";
CM_ SG_ 2566836222 SPN5High "SPN #5 (Conversion Version 4)";
CM_ SG_ 2566836222 SPN4High "SPN #4 (Conversion Version 4)";
CM_ SG_ 2566836222 SPN3High "SPN #3 (Conversion Version 4)";
CM_ SG_ 2566836222 SPN2High "SPN #2 (Conversion Version 4)";
CM_ SG_ 2566836222 SPN1High "SPN #1 (Conversion Version 4)";
CM_ BO_ 2566835966 "Diagnostic readiness 1";
CM_ SG_ 2566835966 OBDCompliance "Identifies the OBD compliance capabilityof the responding controller.";
CM_ SG_ 2566835966 PreviouslyActiveTroubleCodes "Identifies the number of previously active trouble codes that are present in a specific controller.";
CM_ SG_ 2566835966 ActiveTroubleCodes "Identifies the number of active trouble codes that are present in a specific controller.";
CM_ BO_ 2566835710 "Freeze frame parameters";
CM_ SG_ 2566835710 OccurenceCount1 "The 7 bit occurence count field contains the number of times a fault has gone from active to previously active.";
CM_ SG_ 2566835710 FailureModeIdentifier1 "The FMI defines the type of failure detected in the subsystem identified by an SPN.";
CM_ SG_ 2566835710 SPN1 "SPN #1 (Conversion Version 4)";
CM_ SG_ 2566835710 FreezeFrameLength "The freeze frame length shall be equal to the number of bytes in the required parameters plus the number of bytes in the
manufacturer specific parameters.";
CM_ SG_ 2566835710 EngSpeed "Actual engine speed which is calculated over a minimum crankshaft angle of 720 degrees divided by the number of cylinders.";
CM_ SG_ 2566835710 EngTorqueMode "State signal which indicates which engine torque mode is currently generating, limiting, or controlling the torque.";
CM_ SG_ 2566835710 EngTurboBoostPress "Gage pressure of air measured downstream on the compressor discharge side of the turbocharger.";
CM_ SG_ 2566835710 WheelBasedVehicleSpeed "Speed of the vehicle as calculated from wheel or tailshaft speed.";
CM_ SG_ 2566835710 SPN1High "SPN #1 (Conversion Version 4)";
CM_ BO_ 2566835454 "Diagnostic data clear/reset of previously active DTCs.";
CM_ BO_ 2566764542 "Expanded freeze frame.";
CM_ SG_ 2566764542 OccurenceCount1 "The 7 bit occurence count field contains the number of times a fault has gone from active to previously active.";
CM_ SG_ 2566764542 FailureModeIdentifier1 "The FMI defines the type of failure detected in the subsystem identified by an SPN.";
CM_ SG_ 2566764542 SPN1 "SPN #1 (Conversion Version 4)";
CM_ SG_ 2566764542 ExpandedFreezeFrameLength "The freeze frame length shall be equal to the number of bytes in the required parameters plus the number of bytes in the
manufacturer specific parameters.";
CM_ SG_ 2566764542 SPN1High "SPN #1 (Conversion Version 4)";
CM_ BO_ 2566764286 "SPN Support. This message is used to identify those SPNs supported by the product for freeze frames and data stream messages.";
CM_ SG_ 2566764286 SPNSupported1High "This parameter defines the SPN(s) that is/are supported for the freeze frame and/or data stream information.";
CM_ SG_ 2566764286 SPNSupportTypeSTR3 "This parameter defines whether the applicable parameter (that is the SPN) is supported in the freeze frame, the data stream or both the freeze frame and data stream.";
CM_ SG_ 2566764286 SPNSupportTypeSTR2 "This parameter defines whether the applicable parameter (that is the SPN) is supported in the freeze frame, the data stream or both the freeze frame and data stream.";
CM_ SG_ 2566764286 SPNSupportTypeEFF3 "This parameter defines whether the applicable parameter (that is the SPN) is supported in the freeze frame, the data stream or both the freeze frame and data stream.";
CM_ SG_ 2566764286 SPNSupportTypeEFF2 "This parameter defines whether the applicable parameter (that is the SPN) is supported in the freeze frame, the data stream or both the freeze frame and data stream.";
CM_ SG_ 2566764286 SPNSupportTypeDS3 "This parameter defines whether the applicable parameter (that is the SPN) is supported in the freeze frame, the data stream or both the freeze frame and data stream.";
CM_ SG_ 2566764286 SPNSupportTypeDS2 "This parameter defines whether the applicable parameter (that is the SPN) is supported in the freeze frame, the data stream or both the freeze frame and data stream.";
CM_ SG_ 2566764286 SPNSupported3High "This parameter defines the SPN(s) that is/are supported for the freeze frame and/or data stream information.";
CM_ SG_ 2566764286 SPNSupported2High "This parameter defines the SPN(s) that is/are supported for the freeze frame and/or data stream information.";
CM_ SG_ 2566764286 SPNSupported3 "This parameter defines the SPN(s) that is/are supported for the freeze frame and/or data stream information.";
CM_ SG_ 2566764286 SPNSupported2 "This parameter defines the SPN(s) that is/are supported for the freeze frame and/or data stream information.";
CM_ SG_ 2566764286 SPNDataLength3 "The number of data bytes associated with the SPN in the Freeze Frame.";
CM_ SG_ 2566764286 SPNSupportTypeSTR1 "This parameter defines whether the applicable parameter (that is the SPN) is supported in the freeze frame, the data stream or both the freeze frame and data stream.";
CM_ SG_ 2566764286 SPNSupportTypeDS1 "This parameter defines whether the applicable parameter (that is the SPN) is supported in the freeze frame, the data stream or both the freeze frame and data stream.";
CM_ SG_ 2566764286 SPNSupportTypeEFF1 "This parameter defines whether the applicable parameter (that is the SPN) is supported in the freeze frame, the data stream or both the freeze frame and data stream.";
CM_ SG_ 2566764286 SPNDataLength2 "The number of data bytes associated with the SPN in the Freeze Frame.";
CM_ SG_ 2566764286 SPNDataLength1 "The number of data bytes associated with the SPN in the Freeze Frame.";
CM_ SG_ 2566764286 SPNSupported1 "This parameter defines the SPN(s) that is/are supported for the freeze frame and/or data stream information.";
CM_ BO_ 2566835198 "Previously active diagnostic trouble codes";
CM_ SG_ 2566835198 SPN5 "SPN #5 (Conversion Version 4)";
CM_ SG_ 2566835198 SPN4 "SPN #4 (Conversion Version 4)";
CM_ SG_ 2566835198 SPN3 "SPN #3 (Conversion Version 4)";
CM_ SG_ 2566835198 SPN2 "SPN #2 (Conversion Version 4)";
CM_ SG_ 2566835198 FailureModeIdentifier5 "The FMI defines the type of failure detected in the subsystem identified by an SPN.";
CM_ SG_ 2566835198 FailureModeIdentifier4 "The FMI defines the type of failure detected in the subsystem identified by an SPN.";
CM_ SG_ 2566835198 OccurenceCount1 "The 7 bit occurence count field contains the number of times a fault has gone from active to previously active.";
CM_ SG_ 2566835198 FailureModeIdentifier1 "The FMI defines the type of failure detected in the subsystem identified by an SPN.";
CM_ SG_ 2566835198 SPN1 "SPN #1 (Conversion Version 4)";
CM_ SG_ 2566835198 MalfunctionIndicatorLampStatus "A lamp used to relay only emissions-related trouble code information.";
CM_ SG_ 2566835198 RedStopLampState "This lamp is uesed to relay trouble code information that is of a severe enought condition that it warrants stopping the vehicle.";
CM_ SG_ 2566835198 AmberWarningLampStatus "This lamp is used to relay trouble code information that is reporting a problem with the vehicle system but the vehicle need
not be immediately stopped.";
CM_ SG_ 2566835198 ProtectLampStatus "This lamp is used to relay trouble code informatio that is reporting a problem with a vehicle system that is most
probably not electronic subsystem related.";
CM_ SG_ 2566835198 FailureModeIdentifier3 "The FMI defines the type of failure detected in the subsystem identified by an SPN.";
CM_ SG_ 2566835198 FlashRedStopLamp "This parameter provides the capability to flash the RSL (SPN 3039).";
CM_ SG_ 2566835198 FlashProtectLamp "This parameter provides the capability to flash the engine protect lamp (SPN 3041).";
CM_ SG_ 2566835198 FlashMalfuncIndicatorLamp "This parameter provides the capability to flash the MIL (SPN 3038).";
CM_ SG_ 2566835198 FlashAmberWarningLamp "This parameter provides the capability to flash the AWL (SPN 3040). ";
CM_ SG_ 2566835198 FailureModeIdentifier2 "The FMI defines the type of failure detected in the subsystem identified by an SPN.";
CM_ SG_ 2566835198 OccurenceCount5 "The 7 bit occurence count field contains the number of times a fault has gone from active to previously active.";
CM_ SG_ 2566835198 OccurenceCount4 "The 7 bit occurence count field contains the number of times a fault has gone from active to previously active.";
CM_ SG_ 2566835198 OccurenceCount3 "The 7 bit occurence count field contains the number of times a fault has gone from active to previously active.";
CM_ SG_ 2566835198 OccurenceCount2 "The 7 bit occurence count field contains the number of times a fault has gone from active to previously active.";
CM_ SG_ 2566835198 SPN5High "SPN #5 (Conversion Version 4)";
CM_ SG_ 2566835198 SPN4High "SPN #4 (Conversion Version 4)";
CM_ SG_ 2566835198 SPN3High "SPN #3 (Conversion Version 4)";
CM_ SG_ 2566835198 SPN2High "SPN #2 (Conversion Version 4)";
CM_ SG_ 2566835198 SPN1High "SPN #1 (Conversion Version 4)";
CM_ BO_ 2564030206 "Calibration Information";
CM_ BO_ 2566837502 "Emissions-related active diagnostic trouble codes.";
CM_ SG_ 2566837502 SPN5 "SPN #5 (Conversion Version 4)";
CM_ SG_ 2566837502 SPN4 "SPN #4 (Conversion Version 4)";
CM_ SG_ 2566837502 SPN3 "SPN #3 (Conversion Version 4)";
CM_ SG_ 2566837502 SPN2 "SPN #2 (Conversion Version 4)";
CM_ SG_ 2566837502 FlashRedStopLamp "This parameter provides the capability to flash the RSL (SPN 3039).";
CM_ SG_ 2566837502 FlashProtectLamp "This parameter provides the capability to flash the engine protect lamp (SPN 3041).";
CM_ SG_ 2566837502 FailureModeIdentifier5 "The FMI defines the type of failure detected in the subsystem identified by an SPN.";
CM_ SG_ 2566837502 FailureModeIdentifier4 "The FMI defines the type of failure detected in the subsystem identified by an SPN.";
CM_ SG_ 2566837502 FailureModeIdentifier3 "The FMI defines the type of failure detected in the subsystem identified by an SPN.";
CM_ SG_ 2566837502 OccurenceCount1 "The 7 bit occurence count field contains the number of times a fault has gone from active to previously active.";
CM_ SG_ 2566837502 FailureModeIdentifier1 "The FMI defines the type of failure detected in the subsystem identified by an SPN.";
CM_ SG_ 2566837502 SPN1 "SPN #1 (Conversion Version 4)";
CM_ SG_ 2566837502 MalfunctionIndicatorLampStatus "A lamp used to relay only emissions-related trouble code information.";
CM_ SG_ 2566837502 RedStopLampState "This lamp is uesed to relay trouble code information that is of a severe enought condition that it warrants stopping the vehicle.";
CM_ SG_ 2566837502 AmberWarningLampStatus "This lamp is used to relay trouble code information that is reporting a problem with the vehicle system but the vehicle need
not be immediately stopped.";
CM_ SG_ 2566837502 ProtectLampStatus "This lamp is used to relay trouble code informatio that is reporting a problem with a vehicle system that is most
probably not electronic subsystem related.";
CM_ SG_ 2566837502 FlashMalfuncIndicatorLamp "This parameter provides the capability to flash the MIL (SPN 3038).";
CM_ SG_ 2566837502 FlashAmberWarningLamp "This parameter provides the capability to flash the AWL (SPN 3040). ";
CM_ SG_ 2566837502 FailureModeIdentifier2 "The FMI defines the type of failure detected in the subsystem identified by an SPN.";
CM_ SG_ 2566837502 OccurenceCount5 "The 7 bit occurence count field contains the number of times a fault has gone from active to previously active.";
CM_ SG_ 2566837502 OccurenceCount4 "The 7 bit occurence count field contains the number of times a fault has gone from active to previously active.";
CM_ SG_ 2566837502 OccurenceCount3 "The 7 bit occurence count field contains the number of times a fault has gone from active to previously active.";
CM_ SG_ 2566837502 OccurenceCount2 "The 7 bit occurence count field contains the number of times a fault has gone from active to previously active.";
CM_ SG_ 2566837502 SPN5High "SPN #5 (Conversion Version 4)";
CM_ SG_ 2566837502 SPN4High "SPN #4 (Conversion Version 4)";
CM_ SG_ 2566837502 SPN3High "SPN #3 (Conversion Version 4)";
CM_ SG_ 2566837502 SPN2High "SPN #2 (Conversion Version 4)";
CM_ SG_ 2566837502 SPN1High "SPN #1 (Conversion Version 4)";
CM_ BO_ 2566834942 "Active diagnostic trouble codes";
CM_ SG_ 2566834942 SPN5 "SPN #5 (Conversion Version 4)";
CM_ SG_ 2566834942 SPN4 "SPN #4 (Conversion Version 4)";
CM_ SG_ 2566834942 SPN3 "SPN #3 (Conversion Version 4)";
CM_ SG_ 2566834942 SPN2 "SPN #2 (Conversion Version 4)";
CM_ SG_ 2566834942 FailureModeIdentifier5 "The FMI defines the type of failure detected in the subsystem identified by an SPN.";
CM_ SG_ 2566834942 FailureModeIdentifier4 "The FMI defines the type of failure detected in the subsystem identified by an SPN.";
CM_ SG_ 2566834942 FailureModeIdentifier3 "The FMI defines the type of failure detected in the subsystem identified by an SPN.";
CM_ SG_ 2566834942 FlashRedStopLamp "This parameter provides the capability to flash the RSL (SPN 3039).";
CM_ SG_ 2566834942 FlashProtectLamp "This parameter provides the capability to flash the engine protect lamp (SPN 3041).";
CM_ SG_ 2566834942 FlashMalfuncIndicatorLamp "This parameter provides the capability to flash the MIL (SPN 3038).";
CM_ SG_ 2566834942 FlashAmberWarningLamp "This parameter provides the capability to flash the AWL (SPN 3040). ";
CM_ SG_ 2566834942 MalfunctionIndicatorLampStatus "A lamp used to relay only emissions-related trouble code information.";
CM_ SG_ 2566834942 AmberWarningLampStatus "This lamp is used to relay trouble code information that is reporting a problem with the vehicle system but the vehicle need
not be immediately stopped.";
CM_ SG_ 2566834942 OccurenceCount1 "The 7 bit occurence count field contains the number of times a fault has gone from active to previously active.";
CM_ SG_ 2566834942 FailureModeIdentifier1 "The FMI defines the type of failure detected in the subsystem identified by an SPN.";
CM_ SG_ 2566834942 SPN1 "SPN #1 (Conversion Version 4)";
CM_ SG_ 2566834942 RedStopLampState "This lamp is uesed to relay trouble code information that is of a severe enought condition that it warrants stopping the vehicle.";
CM_ SG_ 2566834942 ProtectLampStatus "This lamp is used to relay trouble code informatio that is reporting a problem with a vehicle system that is most
probably not electronic subsystem related.";
CM_ SG_ 2566834942 FailureModeIdentifier2 "The FMI defines the type of failure detected in the subsystem identified by an SPN.";
CM_ SG_ 2566834942 OccurenceCount5 "The 7 bit occurence count field contains the number of times a fault has gone from active to previously active.";
CM_ SG_ 2566834942 OccurenceCount4 "The 7 bit occurence count field contains the number of times a fault has gone from active to previously active.";
CM_ SG_ 2566834942 OccurenceCount3 "The 7 bit occurence count field contains the number of times a fault has gone from active to previously active.";
CM_ SG_ 2566834942 OccurenceCount2 "The 7 bit occurence count field contains the number of times a fault has gone from active to previously active.";
CM_ SG_ 2566834942 SPN5High "SPN #5 (Conversion Version 4)";
CM_ SG_ 2566834942 SPN4High "SPN #4 (Conversion Version 4)";
CM_ SG_ 2566834942 SPN3High "SPN #3 (Conversion Version 4)";
CM_ SG_ 2566834942 SPN2High "SPN #2 (Conversion Version 4)";
CM_ SG_ 2566834942 SPN1High "SPN #1 (Conversion Version 4)";
CM_ BO_ 2565799678 "Address Claimed";
CM_ SG_ 2565799678 IndustryGroup "0 = Global; 
   1  = On-Highway; 
   2  = Agricultural and Forestry; 
   3  = Construction; 
   4  = Marine;
   5  = Industrial - Process
          Control - Stationary (Gen-Sets)
   6  = Reserve for SAE
   7  = Reserve for SAE";
CM_ SG_ 2565799678 ManufacturerCode "Assigned by NMEA 2000 Committee";
CM_ BO_ 2563440382 "Transfer";
CM_ SG_ 2563440382 ShrtNameOfActualReportingDevice "Short name of reporting device of the requested PGN via the Transfer PGN.";
CM_ SG_ 2563440382 LengthOfDataForTheReportedPGN "Length of data reported with the associated PGN via the Transfer PGN.";
CM_ SG_ 2563440382 PGNofRequstedInformation "PGN associated with this transfer message";
CM_ BO_ 2565603070 "Transport Protocol - Data Transfer";
CM_ BO_ 2565668606 "Transport Protocol - Connection Management";
CM_ SG_ 2565668606 TotalNumberOfPacketsEoMA "Total number of packets for BAM message.Total number of packets received for RTS/CTS message.Total number of packets for RTS/CTS message.";
CM_ SG_ 2565668606 TotalMessageSizeEoMA "Total message size (in bytes) for BAM message.Total message size (in bytes) for RTS/CTS message.Total message size (in bytes) for RTS/CTS message.";
CM_ SG_ 2565668606 TotalMessageSizeBAM "Total message size (in bytes) for BAM message.Total message size (in bytes) for RTS/CTS message.Total message size (in bytes) for RTS/CTS message.";
CM_ SG_ 2565668606 TotalNumberOfPacketsBAM "Total number of packets for BAM message.Total number of packets received for RTS/CTS message.Total number of packets for RTS/CTS message.";
CM_ SG_ 2565668606 ConnectionAbortReason "Reason for connection abort message.";
CM_ SG_ 2565668606 NextPacketNumberToBeSent "Next Packet Number to be sent (TP.CM_CTS)";
CM_ SG_ 2565668606 NumberOfPacketsThatCanBeSent "Number of Packets that can be sent (TP.CM_CTS)";
CM_ SG_ 2565668606 MaximumNumberOfPackets "Maximum number of packets for RTS/CTS message.";
CM_ SG_ 2565668606 TotalNumberOfPackets "Total number of packets for BAM message.Total number of packets received for RTS/CTS message.Total number of packets for RTS/CTS message.";
CM_ SG_ 2565668606 TotalMessageSize "Total message size (in bytes) for BAM message.Total message size (in bytes) for RTS/CTS message.Total message size (in bytes) for RTS/CTS message.";
CM_ BO_ 2563374846 "Request 2";
CM_ SG_ 2563374846 UseTransferMode "Requester is to respond via the Transfer PGN";
CM_ SG_ 2563374846 ParameterGroupNumber "PGN which is requested by Request2 message";
CM_ BO_ 2565537534 "Request";
CM_ SG_ 2565537534 ParameterGroupNumber "PGN which is requested by Request2 message";
CM_ BO_ 2565406462 "Acknowledgment Message";
CM_ SG_ 2565406462 ParameterGroupNumber "PGN which is requested by Request2 message";
CM_ SG_ 2565406462 GroupFunctionValue "Indicates the acknowledgement response.Indicates the acknowledgement response.Negative Acknowledgement Group Function valuePositive Acknowledgement Group Function value";
CM_ EV_ EnvTPMS_Recalibrate "Recalibrate tire monitoring system";
BA_DEF_ SG_  "SigType" ENUM  "Default","Range","RangeSigned","ASCII","Discrete","Control","ReferencePGN","DTC","StringDelimiter","StringLength","StringLengthControl";
BA_DEF_ SG_  "GenSigStartValue" FLOAT 0 10000;
BA_DEF_ SG_  "GenSigSendType" ENUM  "Cyclic","OnWrite","reserved","OnChange","reserved","reserved","reserved","NoSigSendType";
BA_DEF_ SG_  "GenSigILSupport" ENUM  "Yes","No";
BA_DEF_ BO_  "GenMsgILSupport" ENUM  "Yes","No";
BA_DEF_ SG_  "SPN" INT 0 524287;
BA_DEF_ BO_  "GenMsgRequestable" INT 0 1;
BA_DEF_ BO_  "GenMsgSendType" ENUM  "cyclic","reserved","cyclicIfActive","reserved","reserved","reserved","reserved","reserved","noMsgSendType";
BA_DEF_ BO_  "VFrameFormat" ENUM  "StandardCAN","ExtendedCAN","reserved","J1939PG";
BA_DEF_ BO_  "GenMsgCycleTime" INT 0 3600000;
BA_DEF_ BU_  "NodeLayerModules" STRING ;
BA_DEF_ BU_  "NmStationAddress" INT 0 255;
BA_DEF_ BU_  "NmJ1939AAC" INT 0 1;
BA_DEF_ BU_  "NmJ1939IndustryGroup" INT 0 7;
BA_DEF_ BU_  "NmJ1939System" INT 0 127;
BA_DEF_ BU_  "NmJ1939SystemInstance" INT 0 15;
BA_DEF_ BU_  "NmJ1939Function" INT 0 255;
BA_DEF_ BU_  "NmJ1939FunctionInstance" INT 0 7;
BA_DEF_ BU_  "NmJ1939ECUInstance" INT 0 3;
BA_DEF_ BU_  "NmJ1939ManufacturerCode" INT 0 2047;
BA_DEF_ BU_  "NmJ1939IdentityNumber" INT 0 2097151;
BA_DEF_ BU_  "ECU" STRING ;
BA_DEF_  "DatabaseVersion" STRING ;
BA_DEF_  "BusType" STRING ;
BA_DEF_  "ProtocolType" STRING ;
BA_DEF_DEF_  "SigType" "Default";
BA_DEF_DEF_  "GenSigStartValue" 0;
BA_DEF_DEF_  "GenSigSendType" "NoSigSendType";
BA_DEF_DEF_  "GenSigILSupport" "Yes";
BA_DEF_DEF_  "GenMsgILSupport" "Yes";
BA_DEF_DEF_  "SPN" 0;
BA_DEF_DEF_  "GenMsgRequestable" 1;
BA_DEF_DEF_  "GenMsgSendType" "noMsgSendType";
BA_DEF_DEF_  "VFrameFormat" "J1939PG";
BA_DEF_DEF_  "GenMsgCycleTime" 0;
BA_DEF_DEF_  "NodeLayerModules" "";
BA_DEF_DEF_  "NmStationAddress" 254;
BA_DEF_DEF_  "NmJ1939AAC" 0;
BA_DEF_DEF_  "NmJ1939IndustryGroup" 0;
BA_DEF_DEF_  "NmJ1939System" 0;
BA_DEF_DEF_  "NmJ1939SystemInstance" 0;
BA_DEF_DEF_  "NmJ1939Function" 0;
BA_DEF_DEF_  "NmJ1939FunctionInstance" 0;
BA_DEF_DEF_  "NmJ1939ECUInstance" 0;
BA_DEF_DEF_  "NmJ1939ManufacturerCode" 0;
BA_DEF_DEF_  "NmJ1939IdentityNumber" 0;
BA_DEF_DEF_  "ECU" "";
BA_DEF_DEF_  "DatabaseVersion" "";
BA_DEF_DEF_  "BusType" "";
BA_DEF_DEF_  "ProtocolType" "";
BA_ "DatabaseVersion" "7.0";
BA_ "ProtocolType" "J1939";
BA_ "BusType" "CAN";
BA_ "NmStationAddress" BU_ TPMS 51;
BA_ "NmJ1939Function" BU_ TPMS 38;
BA_ "NmJ1939ManufacturerCode" BU_ TPMS 1861;
BA_ "NmJ1939IdentityNumber" BU_ TPMS 603215;
BA_ "ECU" BU_ TPMS "TPMS";
BA_ "NodeLayerModules" BU_ TPMS "J1939_IL.dll";
BA_ "GenMsgCycleTime" BO_ 2566845491 10000;
BA_ "GenMsgSendType" BO_ 2566845491 0;
BA_ "SigType" SG_ 2566838526 IndustryGroup 4;
BA_ "SigType" SG_ 2566838526 ManufacturerCode 1;
BA_ "SigType" SG_ 2566838526 AddressAssignment 1;
BA_ "SPN" SG_ 2566838526 AddressAssignment 2847;
BA_ "SigType" SG_ 2561605374 ReferenceTirePressSetting 1;
BA_ "SPN" SG_ 2561605374 ReferenceTirePressSetting 3193;
BA_ "SigType" SG_ 2561605374 TireLocation 1;
BA_ "SPN" SG_ 2561605374 TireLocation 929;
BA_ "SPN" SG_ 2562981630 IndividualDTCClearControlByte 3034;
BA_ "SPN" SG_ 2562981630 CtrlByteIndicIndividualDTCClear 3035;
BA_ "SPN" SG_ 2562981630 SPN1 1214;
BA_ "SPN" SG_ 2562981630 SPN1High 1214;
BA_ "SPN" SG_ 2562981630 FailureModeIdentifier1 1215;
BA_ "SigType" SG_ 2566764851 ReferenceTirePress 1;
BA_ "SPN" SG_ 2566764851 ReferenceTirePress 3191;
BA_ "SigType" SG_ 2566764851 TireLocation 1;
BA_ "SPN" SG_ 2566764851 TireLocation 929;
BA_ "SigType" SG_ 2566845491 TirePressThresholdDetection 4;
BA_ "SPN" SG_ 2566845491 TirePressThresholdDetection 2587;
BA_ "GenSigILSupport" SG_ 2566845491 TirePressThresholdDetection 1;
BA_ "SigType" SG_ 2566845491 TireAirLeakageRate 1;
BA_ "SPN" SG_ 2566845491 TireAirLeakageRate 2586;
BA_ "GenSigILSupport" SG_ 2566845491 TireAirLeakageRate 1;
BA_ "SigType" SG_ 2566845491 CTIWheelEndElectricalFault 4;
BA_ "SPN" SG_ 2566845491 CTIWheelEndElectricalFault 1697;
BA_ "GenSigILSupport" SG_ 2566845491 CTIWheelEndElectricalFault 1;
BA_ "SigType" SG_ 2566845491 CTITireStatus 4;
BA_ "SPN" SG_ 2566845491 CTITireStatus 1698;
BA_ "GenSigILSupport" SG_ 2566845491 CTITireStatus 1;
BA_ "SigType" SG_ 2566845491 CTIWheelSensorStatus 4;
BA_ "SPN" SG_ 2566845491 CTIWheelSensorStatus 1699;
BA_ "GenSigILSupport" SG_ 2566845491 CTIWheelSensorStatus 1;
BA_ "SigType" SG_ 2566845491 TireTemp 1;
BA_ "GenSigStartValue" SG_ 2566845491 TireTemp 9312;
BA_ "SPN" SG_ 2566845491 TireTemp 242;
BA_ "SigType" SG_ 2566845491 TirePress 1;
BA_ "SPN" SG_ 2566845491 TirePress 241;
BA_ "SigType" SG_ 2566845491 TireLocation 1;
BA_ "SPN" SG_ 2566845491 TireLocation 929;
BA_ "SigType" SG_ 2566839038 NmbrOfSftwrIdentificationFields 1;
BA_ "SPN" SG_ 2566839038 NmbrOfSftwrIdentificationFields 965;
BA_ "SPN" SG_ 2566836222 FlashRedStopLamp 3039;
BA_ "SPN" SG_ 2566836222 FlashProtectLamp 3041;
BA_ "SigType" SG_ 2566836222 FlashMalfuncIndicatorLamp 4;
BA_ "SPN" SG_ 2566836222 FlashMalfuncIndicatorLamp 3038;
BA_ "SPN" SG_ 2566836222 FlashAmberWarningLamp 3040;
BA_ "SigType" SG_ 2566836222 OccurenceCount5 1;
BA_ "SigType" SG_ 2566836222 OccurenceCount4 1;
BA_ "SigType" SG_ 2566836222 OccurenceCount3 1;
BA_ "SigType" SG_ 2566836222 OccurenceCount2 1;
BA_ "SigType" SG_ 2566836222 OccurenceCount1 1;
BA_ "SPN" SG_ 2566836222 OccurenceCount1 1216;
BA_ "SPN" SG_ 2566836222 SPNConversionMethod1 1706;
BA_ "SPN" SG_ 2566836222 FailureModeIdentifier1 1215;
BA_ "SPN" SG_ 2566836222 SPN1 1214;
BA_ "SigType" SG_ 2566836222 MalfunctionIndicatorLampStatus 4;
BA_ "SPN" SG_ 2566836222 MalfunctionIndicatorLampStatus 1213;
BA_ "SigType" SG_ 2566836222 RedStopLampState 4;
BA_ "SPN" SG_ 2566836222 RedStopLampState 623;
BA_ "SigType" SG_ 2566836222 AmberWarningLampStatus 4;
BA_ "SPN" SG_ 2566836222 AmberWarningLampStatus 624;
BA_ "SigType" SG_ 2566836222 ProtectLampStatus 4;
BA_ "SPN" SG_ 2566836222 ProtectLampStatus 987;
BA_ "SPN" SG_ 2566836222 SPN1High 1214;
BA_ "SPN" SG_ 2566835966 MisfireMonitoringSupport 1221;
BA_ "SigType" SG_ 2566835966 OBDCompliance 1;
BA_ "SPN" SG_ 2566835966 OBDCompliance 1220;
BA_ "SigType" SG_ 2566835966 PreviouslyActiveTroubleCodes 1;
BA_ "SPN" SG_ 2566835966 PreviouslyActiveTroubleCodes 1219;
BA_ "SigType" SG_ 2566835966 ActiveTroubleCodes 1;
BA_ "SPN" SG_ 2566835966 ActiveTroubleCodes 1218;
BA_ "SPN" SG_ 2566835966 SecondAirSystemMonStatus 1223;
BA_ "SPN" SG_ 2566835966 EvaporativeSystemMonStatus 1223;
BA_ "SPN" SG_ 2566835966 ACSystemRefrigerantMonStatus 1223;
BA_ "SPN" SG_ 2566835966 OxygenSensorHeaterMonStatus 1223;
BA_ "SPN" SG_ 2566835966 OxygenSensorMonStatus 1223;
BA_ "SPN" SG_ 2566835966 EGRSystemMonitoringStatus 1223;
BA_ "SPN" SG_ 2566835966 CatalystMonStatus 1223;
BA_ "SPN" SG_ 2566835966 ColdStartAidSystemMonStatus 1223;
BA_ "SPN" SG_ 2566835966 HeatedCatalystMonStatus 1223;
BA_ "SPN" SG_ 2566835966 CatalystMonSupp 1222;
BA_ "SPN" SG_ 2566835966 ColdStartAidSystemMonSupp 1222;
BA_ "SPN" SG_ 2566835966 HeatedCatalystMonSupp 1222;
BA_ "SPN" SG_ 2566835966 EvaporativeSystemMonSupp 1222;
BA_ "SPN" SG_ 2566835966 SecondAirSystemMonSupp 1222;
BA_ "SPN" SG_ 2566835966 ACSystemRefrigerantMonSupp 1222;
BA_ "SPN" SG_ 2566835966 OxygenSensorMonSupp 1222;
BA_ "SPN" SG_ 2566835966 OxygenSensorHeaterMonSupp 1222;
BA_ "SPN" SG_ 2566835966 EGRSystemMonitoringSupp 1222;
BA_ "SPN" SG_ 2566835966 MisfireMonitoringStatus 1221;
BA_ "SPN" SG_ 2566835966 ComprehensiveCompMonStatus 1221;
BA_ "SPN" SG_ 2566835966 FuelSystemMonitoringStatus 1221;
BA_ "SPN" SG_ 2566835966 ComprehensiveComponentMonSupp 1221;
BA_ "SPN" SG_ 2566835966 FuelSystemMonitoringSupport 1221;
BA_ "SigType" SG_ 2566835710 OccurenceCount1 1;
BA_ "SPN" SG_ 2566835710 OccurenceCount1 1216;
BA_ "SPN" SG_ 2566835710 SPNConversionMethod1 1706;
BA_ "SPN" SG_ 2566835710 FailureModeIdentifier1 1215;
BA_ "SPN" SG_ 2566835710 SPN1 1214;
BA_ "SPN" SG_ 2566835710 FreezeFrameLength 1217;
BA_ "SigType" SG_ 2566835710 EngSpeed 1;
BA_ "SPN" SG_ 2566835710 EngSpeed 190;
BA_ "SigType" SG_ 2566835710 EngTorqueMode 4;
BA_ "SPN" SG_ 2566835710 EngTorqueMode 899;
BA_ "SigType" SG_ 2566835710 EngTurboBoostPress 1;
BA_ "SPN" SG_ 2566835710 EngTurboBoostPress 102;
BA_ "SigType" SG_ 2566835710 WheelBasedVehicleSpeed 1;
BA_ "SPN" SG_ 2566835710 WheelBasedVehicleSpeed 84;
BA_ "SigType" SG_ 2566835710 EngPercentLoadAtCurrentSpeed 1;
BA_ "SPN" SG_ 2566835710 EngPercentLoadAtCurrentSpeed 92;
BA_ "SigType" SG_ 2566835710 EngineCoolantTemperature 1;
BA_ "SPN" SG_ 2566835710 EngineCoolantTemperature 110;
BA_ "SPN" SG_ 2566835710 SPN1High 1214;
BA_ "SigType" SG_ 2566764542 OccurenceCount1 1;
BA_ "SPN" SG_ 2566764542 OccurenceCount1 1216;
BA_ "SPN" SG_ 2566764542 SPNConversionMethod1 1706;
BA_ "SPN" SG_ 2566764542 FailureModeIdentifier1 1215;
BA_ "SPN" SG_ 2566764542 SPN1 1214;
BA_ "SPN" SG_ 2566764542 ExpandedFreezeFrameLength 3149;
BA_ "SPN" SG_ 2566764542 SPN1High 1214;
BA_ "SPN" SG_ 2566764286 SPNSupported1High 3146;
BA_ "SPN" SG_ 2566764286 SPNSupported3High 3146;
BA_ "SPN" SG_ 2566764286 SPNSupported2High 3146;
BA_ "SPN" SG_ 2566764286 SPNSupported3 3146;
BA_ "SPN" SG_ 2566764286 SPNSupported2 3146;
BA_ "SPN" SG_ 2566764286 SPNDataLength3 3148;
BA_ "SPN" SG_ 2566764286 SPNDataLength2 3148;
BA_ "SPN" SG_ 2566764286 SPNDataLength1 3148;
BA_ "SPN" SG_ 2566764286 SPNSupported1 3146;
BA_ "SigType" SG_ 2566835198 OccurenceCount1 1;
BA_ "SPN" SG_ 2566835198 OccurenceCount1 1216;
BA_ "SPN" SG_ 2566835198 SPNConversionMethod1 1706;
BA_ "SPN" SG_ 2566835198 FailureModeIdentifier1 1215;
BA_ "SPN" SG_ 2566835198 SPN1 1214;
BA_ "SigType" SG_ 2566835198 MalfunctionIndicatorLampStatus 4;
BA_ "SPN" SG_ 2566835198 MalfunctionIndicatorLampStatus 1213;
BA_ "SigType" SG_ 2566835198 RedStopLampState 4;
BA_ "SPN" SG_ 2566835198 RedStopLampState 623;
BA_ "SigType" SG_ 2566835198 AmberWarningLampStatus 4;
BA_ "SPN" SG_ 2566835198 AmberWarningLampStatus 624;
BA_ "SigType" SG_ 2566835198 ProtectLampStatus 4;
BA_ "SPN" SG_ 2566835198 ProtectLampStatus 987;
BA_ "SPN" SG_ 2566835198 FlashRedStopLamp 3039;
BA_ "SPN" SG_ 2566835198 FlashProtectLamp 3041;
BA_ "SigType" SG_ 2566835198 FlashMalfuncIndicatorLamp 4;
BA_ "SPN" SG_ 2566835198 FlashMalfuncIndicatorLamp 3038;
BA_ "SPN" SG_ 2566835198 FlashAmberWarningLamp 3040;
BA_ "SigType" SG_ 2566835198 OccurenceCount5 1;
BA_ "SigType" SG_ 2566835198 OccurenceCount4 1;
BA_ "SigType" SG_ 2566835198 OccurenceCount3 1;
BA_ "SigType" SG_ 2566835198 OccurenceCount2 1;
BA_ "SPN" SG_ 2566835198 SPN1High 1214;
BA_ "SPN" SG_ 2564030206 CalibrationID4 1635;
BA_ "SPN" SG_ 2564030206 CalibrationID3 1635;
BA_ "SPN" SG_ 2564030206 CalibrationID2 1635;
BA_ "SPN" SG_ 2564030206 CalibrationID1 1635;
BA_ "SigType" SG_ 2564030206 CalibrationVerificationNumber 1;
BA_ "SPN" SG_ 2564030206 CalibrationVerificationNumber 1634;
BA_ "SPN" SG_ 2566837502 FlashRedStopLamp 3039;
BA_ "SPN" SG_ 2566837502 FlashProtectLamp 3041;
BA_ "SigType" SG_ 2566837502 OccurenceCount1 1;
BA_ "SPN" SG_ 2566837502 OccurenceCount1 1216;
BA_ "SPN" SG_ 2566837502 SPNConversionMethod1 1706;
BA_ "SPN" SG_ 2566837502 FailureModeIdentifier1 1215;
BA_ "SPN" SG_ 2566837502 SPN1 1214;
BA_ "SigType" SG_ 2566837502 MalfunctionIndicatorLampStatus 4;
BA_ "SPN" SG_ 2566837502 MalfunctionIndicatorLampStatus 1213;
BA_ "SigType" SG_ 2566837502 RedStopLampState 4;
BA_ "SPN" SG_ 2566837502 RedStopLampState 623;
BA_ "SigType" SG_ 2566837502 AmberWarningLampStatus 4;
BA_ "SPN" SG_ 2566837502 AmberWarningLampStatus 624;
BA_ "SigType" SG_ 2566837502 ProtectLampStatus 4;
BA_ "SPN" SG_ 2566837502 ProtectLampStatus 987;
BA_ "SigType" SG_ 2566837502 FlashMalfuncIndicatorLamp 4;
BA_ "SPN" SG_ 2566837502 FlashMalfuncIndicatorLamp 3038;
BA_ "SPN" SG_ 2566837502 FlashAmberWarningLamp 3040;
BA_ "SigType" SG_ 2566837502 OccurenceCount5 1;
BA_ "SigType" SG_ 2566837502 OccurenceCount4 1;
BA_ "SigType" SG_ 2566837502 OccurenceCount3 1;
BA_ "SigType" SG_ 2566837502 OccurenceCount2 1;
BA_ "SPN" SG_ 2566837502 SPN1High 1214;
BA_ "SPN" SG_ 2566834942 FlashRedStopLamp 3039;
BA_ "SPN" SG_ 2566834942 FlashProtectLamp 3041;
BA_ "SigType" SG_ 2566834942 FlashMalfuncIndicatorLamp 4;
BA_ "SPN" SG_ 2566834942 FlashMalfuncIndicatorLamp 3038;
BA_ "SPN" SG_ 2566834942 FlashAmberWarningLamp 3040;
BA_ "SigType" SG_ 2566834942 MalfunctionIndicatorLampStatus 4;
BA_ "SPN" SG_ 2566834942 MalfunctionIndicatorLampStatus 1213;
BA_ "SigType" SG_ 2566834942 AmberWarningLampStatus 4;
BA_ "SPN" SG_ 2566834942 AmberWarningLampStatus 624;
BA_ "SigType" SG_ 2566834942 OccurenceCount1 1;
BA_ "SPN" SG_ 2566834942 OccurenceCount1 1216;
BA_ "SPN" SG_ 2566834942 SPNConversionMethod1 1706;
BA_ "SPN" SG_ 2566834942 FailureModeIdentifier1 1215;
BA_ "SPN" SG_ 2566834942 SPN1 1214;
BA_ "SigType" SG_ 2566834942 RedStopLampState 4;
BA_ "SPN" SG_ 2566834942 RedStopLampState 623;
BA_ "SigType" SG_ 2566834942 ProtectLampStatus 4;
BA_ "SPN" SG_ 2566834942 ProtectLampStatus 987;
BA_ "SigType" SG_ 2566834942 OccurenceCount5 1;
BA_ "SigType" SG_ 2566834942 OccurenceCount4 1;
BA_ "SigType" SG_ 2566834942 OccurenceCount3 1;
BA_ "SigType" SG_ 2566834942 OccurenceCount2 1;
BA_ "SPN" SG_ 2566834942 SPN1High 1214;
BA_ "SigType" SG_ 2565799678 IndustryGroup 4;
BA_ "SigType" SG_ 2565799678 ManufacturerCode 1;
BA_ "SigType" SG_ 2563440382 ShrtNameOfActualReportingDevice 4;
BA_ "SPN" SG_ 2563440382 ShrtNameOfActualReportingDevice 2554;
BA_ "SigType" SG_ 2563440382 LengthOfDataForTheReportedPGN 1;
BA_ "SPN" SG_ 2563440382 LengthOfDataForTheReportedPGN 2553;
BA_ "SigType" SG_ 2563440382 PGNofRequstedInformation 1;
BA_ "SPN" SG_ 2563440382 PGNofRequstedInformation 2552;
BA_ "SigType" SG_ 2565603070 SequenceNumber 1;
BA_ "SPN" SG_ 2565603070 SequenceNumber 2572;
BA_ "SigType" SG_ 2565668606 TotalNumberOfPacketsEoMA 1;
BA_ "SPN" SG_ 2565668606 TotalNumberOfPacketsEoMA 2558;
BA_ "SigType" SG_ 2565668606 TotalMessageSizeEoMA 1;
BA_ "SPN" SG_ 2565668606 TotalMessageSizeEoMA 2557;
BA_ "SigType" SG_ 2565668606 TotalMessageSizeBAM 1;
BA_ "SPN" SG_ 2565668606 TotalMessageSizeBAM 2557;
BA_ "SigType" SG_ 2565668606 TotalNumberOfPacketsBAM 1;
BA_ "SPN" SG_ 2565668606 TotalNumberOfPacketsBAM 2558;
BA_ "SigType" SG_ 2565668606 ConnectionAbortReason 1;
BA_ "SPN" SG_ 2565668606 ConnectionAbortReason 2570;
BA_ "SigType" SG_ 2565668606 NextPacketNumberToBeSent 1;
BA_ "SPN" SG_ 2565668606 NextPacketNumberToBeSent 2562;
BA_ "SigType" SG_ 2565668606 NumberOfPacketsThatCanBeSent 1;
BA_ "SPN" SG_ 2565668606 NumberOfPacketsThatCanBeSent 2561;
BA_ "SPN" SG_ 2565668606 PGNumber 2560;
BA_ "SigType" SG_ 2565668606 MaximumNumberOfPackets 1;
BA_ "SPN" SG_ 2565668606 MaximumNumberOfPackets 2559;
BA_ "SigType" SG_ 2565668606 TotalNumberOfPackets 1;
BA_ "SPN" SG_ 2565668606 TotalNumberOfPackets 2558;
BA_ "SigType" SG_ 2565668606 TotalMessageSize 1;
BA_ "SPN" SG_ 2565668606 TotalMessageSize 2557;
BA_ "SPN" SG_ 2565668606 ControlByte 2556;
BA_ "SigType" SG_ 2563374846 UseTransferMode 4;
BA_ "SPN" SG_ 2563374846 UseTransferMode 2575;
BA_ "SigType" SG_ 2563374846 ParameterGroupNumber 6;
BA_ "SPN" SG_ 2563374846 ParameterGroupNumber 2574;
BA_ "SigType" SG_ 2565537534 ParameterGroupNumber 6;
BA_ "SPN" SG_ 2565537534 ParameterGroupNumber 2574;
BA_ "SigType" SG_ 2565406462 ParameterGroupNumber 6;
BA_ "SPN" SG_ 2565406462 ParameterGroupNumber 2574;
BA_ "SigType" SG_ 2565406462 GroupFunctionValue 1;
BA_ "SPN" SG_ 2565406462 GroupFunctionValue 2542;
BA_ "SPN" SG_ 2565406462 ControlByte 2556;
VAL_ 2566838526 IndustryGroup 7 "Reserve for SAE" 5 "IndustrialProcessCtrlStationary" 4 "Marine" 3 "Construction" 2 "Agricultural and Forestry" 1 "On-Highway" 0 "Global" ;
VAL_ 2562981630 FailureModeIdentifier1 31 "Not available" 19 "Received network data in error" 18 "Below normal (moderately severe)" 17 "Below normal (least severe)" 16 "Above normal (moderately severe)" 15 "Above normal (least severe)" 14 "Special intstructions" 13 "Out of calibration" 12 "Bad intelligent device" 11 "Root cause not known" 10 "Abnormal rate of change" 9 "Abnormal update rate" 8 "Abnormal frequency" 7 "Mechanical system not responding" 6 "Current above normal" 5 "Current below normal" 4 "Voltage below normal" 3 "Voltage above normal" 2 "Data erratic" 1 "Below normal (most severe)" 0 "Above normal (most severe)" ;
VAL_ 2566845491 TirePressThresholdDetection 7 "NotAvailable" 6 "ErrorIndicator" 5 "NotDefined" 4 "ExtrmUndrPrssTrPrssrIsAtALvlWhr" 3 "UndrPrssTrPrssrIsLwrThnThPrssrD" 2 "NWrnngPrssTrPrssrIsWthnThThrshl" 1 "OvrPrssTrPrssrIsHghrThnThPrssrD" 0 "ExtrmOvrPrssTrPrssrIsAtALvlWhrT" ;
VAL_ 2566845491 CTIWheelEndElectricalFault 3 "NotSupported" 2 "Error" 1 "NotDefined" 0 "Ok" ;
VAL_ 2566845491 CTITireStatus 3 "NotSupported" 2 "Error" 1 "TireLeakDetected" 0 "Ok" ;
VAL_ 2566845491 CTIWheelSensorStatus 3 "NotSupported" 2 "NotDefined" 1 "On" 0 "Off_IsolatedFromCTIPressCtrl" ;
VAL_ 2566836222 FailureModeIdentifier5 31 "Not available" 19 "Received network data in error" 18 "Below normal (moderately severe)" 17 "Below normal (least severe)" 16 "Above normal (moderately severe)" 15 "Above normal (least severe)" 14 "Special intstructions" 13 "Out of calibration" 12 "Bad intelligent device" 11 "Root cause not known" 10 "Abnormal rate of change" 9 "Abnormal update rate" 8 "Abnormal frequency" 7 "Mechanical system not responding" 6 "Current above normal" 5 "Current below normal" 4 "Voltage below normal" 3 "Voltage above normal" 2 "Data erratic" 1 "Below normal (most severe)" 0 "Above normal (most severe)" ;
VAL_ 2566836222 FailureModeIdentifier4 31 "Not available" 19 "Received network data in error" 18 "Below normal (moderately severe)" 17 "Below normal (least severe)" 16 "Above normal (moderately severe)" 15 "Above normal (least severe)" 14 "Special intstructions" 13 "Out of calibration" 12 "Bad intelligent device" 11 "Root cause not known" 10 "Abnormal rate of change" 9 "Abnormal update rate" 8 "Abnormal frequency" 7 "Mechanical system not responding" 6 "Current above normal" 5 "Current below normal" 4 "Voltage below normal" 3 "Voltage above normal" 2 "Data erratic" 1 "Below normal (most severe)" 0 "Above normal (most severe)" ;
VAL_ 2566836222 FlashRedStopLamp 3 "Unavailable / Do Not Flash" 2 "Reserved" 1 "Fast Flash" 0 "Slow Flash" ;
VAL_ 2566836222 FlashProtectLamp 3 "Unavailable / Do Not Flash" 2 "Reserved" 1 "Fast Flash" 0 "Slow Flash" ;
VAL_ 2566836222 FlashMalfuncIndicatorLamp 3 "Unavailable / Do Not Flash" 2 "Reserved" 1 "Fast Flash" 0 "Slow Flash" ;
VAL_ 2566836222 FlashAmberWarningLamp 3 "Unavailable / Do Not Flash" 2 "Reserved" 1 "Fast Flash" 0 "Slow Flash" ;
VAL_ 2566836222 FailureModeIdentifier3 31 "Not available" 19 "Received network data in error" 18 "Below normal (moderately severe)" 17 "Below normal (least severe)" 16 "Above normal (moderately severe)" 15 "Above normal (least severe)" 14 "Special intstructions" 13 "Out of calibration" 12 "Bad intelligent device" 11 "Root cause not known" 10 "Abnormal rate of change" 9 "Abnormal update rate" 8 "Abnormal frequency" 7 "Mechanical system not responding" 6 "Current above normal" 5 "Current below normal" 4 "Voltage below normal" 3 "Voltage above normal" 2 "Data erratic" 1 "Below normal (most severe)" 0 "Above normal (most severe)" ;
VAL_ 2566836222 FailureModeIdentifier2 31 "Not available" 19 "Received network data in error" 18 "Below normal (moderately severe)" 17 "Below normal (least severe)" 16 "Above normal (moderately severe)" 15 "Above normal (least severe)" 14 "Special intstructions" 13 "Out of calibration" 12 "Bad intelligent device" 11 "Root cause not known" 10 "Abnormal rate of change" 9 "Abnormal update rate" 8 "Abnormal frequency" 7 "Mechanical system not responding" 6 "Current above normal" 5 "Current below normal" 4 "Voltage below normal" 3 "Voltage above normal" 2 "Data erratic" 1 "Below normal (most severe)" 0 "Above normal (most severe)" ;
VAL_ 2566836222 FailureModeIdentifier1 31 "Not available" 19 "Received network data in error" 18 "Below normal (moderately severe)" 17 "Below normal (least severe)" 16 "Above normal (moderately severe)" 15 "Above normal (least severe)" 14 "Special intstructions" 13 "Out of calibration" 12 "Bad intelligent device" 11 "Root cause not known" 10 "Abnormal rate of change" 9 "Abnormal update rate" 8 "Abnormal frequency" 7 "Mechanical system not responding" 6 "Current above normal" 5 "Current below normal" 4 "Voltage below normal" 3 "Voltage above normal" 2 "Data erratic" 1 "Below normal (most severe)" 0 "Above normal (most severe)" ;
VAL_ 2566836222 MalfunctionIndicatorLampStatus 3 "Not available" 2 "Reserved" 1 "Lamp on" 0 "Lamp off" ;
VAL_ 2566836222 RedStopLampState 3 "Not available" 2 "Reserved" 1 "Lamp on" 0 "Lamp off" ;
VAL_ 2566836222 AmberWarningLampStatus 3 "Not available" 2 "Reserved" 1 "Lamp on" 0 "Lamp off" ;
VAL_ 2566836222 ProtectLampStatus 3 "Not available" 2 "Reserved" 1 "Lamp on" 0 "Lamp off" ;
VAL_ 2566835966 MisfireMonitoringSupport 3 "Not available" 2 "Reserved" 1 "test supported" 0 "test not supported" ;
VAL_ 2566835966 OBDCompliance 5 "Not intended to meet OBD II requ" 4 "OBD I" 3 "OBD and OBD II" 2 "OBD (Federal, EPA)" 1 "OBD II (California, ARB)" 0 "Reserver for assignment by SAE" ;
VAL_ 2566835966 SecondAirSystemMonStatus 1 "TestNotComplete" 0 "TestComplete" ;
VAL_ 2566835966 EvaporativeSystemMonStatus 1 "TestNotComplete" 0 "TestComplete" ;
VAL_ 2566835966 ACSystemRefrigerantMonStatus 1 "TestNotComplete" 0 "TestComplete" ;
VAL_ 2566835966 OxygenSensorHeaterMonStatus 1 "TestNotComplete" 0 "TestComplete" ;
VAL_ 2566835966 OxygenSensorMonStatus 1 "test not complete" 0 "test complete" ;
VAL_ 2566835966 EGRSystemMonitoringStatus 1 "TestNotComplete" 0 "TestComplete" ;
VAL_ 2566835966 CatalystMonStatus 0 "TestComplete" 1 "TestNotComplete" ;
VAL_ 2566835966 ColdStartAidSystemMonStatus 1 "TestNotComplete" 0 "TestComplete" ;
VAL_ 2566835966 HeatedCatalystMonStatus 1 "TestNotComplete" 0 "TestComplete" ;
VAL_ 2566835966 CatalystMonSupp 1 "TestSupported" 0 "TestNotSupported" ;
VAL_ 2566835966 ColdStartAidSystemMonSupp 1 "TestSupported" 0 "TestNotSupported" ;
VAL_ 2566835966 HeatedCatalystMonSupp 1 "TestSupported" 0 "TestNotSupported" ;
VAL_ 2566835966 EvaporativeSystemMonSupp 1 "TestSupported" 0 "TestNotSupported" ;
VAL_ 2566835966 SecondAirSystemMonSupp 1 "TestSupported" 0 "TestNotSupported" ;
VAL_ 2566835966 ACSystemRefrigerantMonSupp 1 "TestSupported" 0 "TestNotSupported" ;
VAL_ 2566835966 OxygenSensorMonSupp 1 "TestSupported" 0 "TestNotSupported" ;
VAL_ 2566835966 OxygenSensorHeaterMonSupp 1 "TestSupported" 0 "TestNotSupported" ;
VAL_ 2566835966 EGRSystemMonitoringSupp 1 "TestSupported" 0 "TestNotSupported" ;
VAL_ 2566835966 MisfireMonitoringStatus 1 "test not complete" 0 "test complete" ;
VAL_ 2566835966 ComprehensiveCompMonStatus 1 "test not complete" 0 "test complete" ;
VAL_ 2566835966 FuelSystemMonitoringStatus 1 "test not complete" 0 "test complete" ;
VAL_ 2566835966 ComprehensiveComponentMonSupp 3 "Not available" 2 "Reserved" 1 "test supported" 0 "test not supported" ;
VAL_ 2566835966 FuelSystemMonitoringSupport 1 "test supported" 0 "test not supported" ;
VAL_ 2566835710 FailureModeIdentifier1 31 "Not available" 19 "Received network data in error" 18 "Below normal (moderately severe)" 17 "Below normal (least severe)" 16 "Above normal (moderately severe)" 15 "Above normal (least severe)" 14 "Special intstructions" 13 "Out of calibration" 12 "Bad intelligent device" 11 "Root cause not known" 10 "Abnormal rate of change" 9 "Abnormal update rate" 8 "Abnormal frequency" 7 "Mechanical system not responding" 6 "Current above normal" 5 "Current below normal" 4 "Voltage below normal" 3 "Voltage above normal" 2 "Data erratic" 1 "Below normal (most severe)" 0 "Above normal (most severe)" ;
VAL_ 2566835710 EngTorqueMode 15 "Not available" 11 "Remote accelerator" 10 "Braking system" 9 "High speed governor" 8 "Torque limiting" 7 "ABS control" 6 "Transmission control" 5 "ASR control" 4 "Road speed governor" 3 "PTO governor" 2 "Cruise control" 1 "Accelerator pedal/operator selec" 0 "Low idle governor/no request (de" ;
VAL_ 2566764542 FailureModeIdentifier1 31 "Not available" 19 "Received network data in error" 18 "Below normal (moderately severe)" 17 "Below normal (least severe)" 16 "Above normal (moderately severe)" 15 "Above normal (least severe)" 14 "Special intstructions" 13 "Out of calibration" 12 "Bad intelligent device" 11 "Root cause not known" 10 "Abnormal rate of change" 9 "Abnormal update rate" 8 "Abnormal frequency" 7 "Mechanical system not responding" 6 "Current above normal" 5 "Current below normal" 4 "Voltage below normal" 3 "Voltage above normal" 2 "Data erratic" 1 "Below normal (most severe)" 0 "Above normal (most severe)" ;
VAL_ 2566764286 SPNSupportTypeSTR3 1 "NotSupportedInScaledTestResults" 0 "SupportedInScaledTestResults" ;
VAL_ 2566764286 SPNSupportTypeSTR2 1 "NotSupportedInScaledTestResults" 0 "SupportedInScaledTestResults" ;
VAL_ 2566764286 SPNSupportTypeEFF3 1 "NotSupportedInExFreezeFrame" 0 "SupportedInExFreezeFrame" ;
VAL_ 2566764286 SPNSupportTypeEFF2 1 "NotSupportedInExFreezeFrame" 0 "SupportedInExFreezeFrame" ;
VAL_ 2566764286 SPNSupportTypeDS3 1 "NotSupportedInDataStream" 0 "SupportedInDataStream" ;
VAL_ 2566764286 SPNSupportTypeDS2 1 "NotSupportedInDataStream" 0 "SupportedInDataStream" ;
VAL_ 2566764286 SPNSupportTypeSTR1 1 "NotSupportedInScaledTestResults" 0 "SupportedInScaledTestResults" ;
VAL_ 2566764286 SPNSupportTypeDS1 1 "NotSupportedInDataStream" 0 "SupportedInDataStream" ;
VAL_ 2566764286 SPNSupportTypeEFF1 1 "NotSupportedInExFreezeFrame" 0 "SupportedInExFreezeFrame" ;
VAL_ 2566835198 FailureModeIdentifier5 31 "Not available" 19 "Received network data in error" 18 "Below normal (moderately severe)" 17 "Below normal (least severe)" 16 "Above normal (moderately severe)" 15 "Above normal (least severe)" 14 "Special intstructions" 13 "Out of calibration" 12 "Bad intelligent device" 11 "Root cause not known" 10 "Abnormal rate of change" 9 "Abnormal update rate" 8 "Abnormal frequency" 7 "Mechanical system not responding" 6 "Current above normal" 5 "Current below normal" 4 "Voltage below normal" 3 "Voltage above normal" 2 "Data erratic" 1 "Below normal (most severe)" 0 "Above normal (most severe)" ;
VAL_ 2566835198 FailureModeIdentifier4 31 "Not available" 19 "Received network data in error" 18 "Below normal (moderately severe)" 17 "Below normal (least severe)" 16 "Above normal (moderately severe)" 15 "Above normal (least severe)" 14 "Special intstructions" 13 "Out of calibration" 12 "Bad intelligent device" 11 "Root cause not known" 10 "Abnormal rate of change" 9 "Abnormal update rate" 8 "Abnormal frequency" 7 "Mechanical system not responding" 6 "Current above normal" 5 "Current below normal" 4 "Voltage below normal" 3 "Voltage above normal" 2 "Data erratic" 1 "Below normal (most severe)" 0 "Above normal (most severe)" ;
VAL_ 2566835198 FailureModeIdentifier1 31 "Not available" 19 "Received network data in error" 18 "Below normal (moderately severe)" 17 "Below normal (least severe)" 16 "Above normal (moderately severe)" 15 "Above normal (least severe)" 14 "Special intstructions" 13 "Out of calibration" 12 "Bad intelligent device" 11 "Root cause not known" 10 "Abnormal rate of change" 9 "Abnormal update rate" 8 "Abnormal frequency" 7 "Mechanical system not responding" 6 "Current above normal" 5 "Current below normal" 4 "Voltage below normal" 3 "Voltage above normal" 2 "Data erratic" 1 "Below normal (most severe)" 0 "Above normal (most severe)" ;
VAL_ 2566835198 MalfunctionIndicatorLampStatus 3 "Not available" 2 "Reserved" 1 "Lamp on" 0 "Lamp off" ;
VAL_ 2566835198 RedStopLampState 3 "Not available" 2 "Reserved" 1 "Lamp on" 0 "Lamp off" ;
VAL_ 2566835198 AmberWarningLampStatus 3 "Not available" 2 "Reserved" 1 "Lamp on" 0 "Lamp off" ;
VAL_ 2566835198 ProtectLampStatus 3 "Not available" 2 "Reserved" 1 "Lamp on" 0 "Lamp off" ;
VAL_ 2566835198 FailureModeIdentifier3 31 "Not available" 19 "Received network data in error" 18 "Below normal (moderately severe)" 17 "Below normal (least severe)" 16 "Above normal (moderately severe)" 15 "Above normal (least severe)" 14 "Special intstructions" 13 "Out of calibration" 12 "Bad intelligent device" 11 "Root cause not known" 10 "Abnormal rate of change" 9 "Abnormal update rate" 8 "Abnormal frequency" 7 "Mechanical system not responding" 6 "Current above normal" 5 "Current below normal" 4 "Voltage below normal" 3 "Voltage above normal" 2 "Data erratic" 1 "Below normal (most severe)" 0 "Above normal (most severe)" ;
VAL_ 2566835198 FlashRedStopLamp 3 "Unavailable / Do Not Flash" 2 "Reserved" 1 "Fast Flash" 0 "Slow Flash" ;
VAL_ 2566835198 FlashProtectLamp 3 "Unavailable / Do Not Flash" 2 "Reserved" 1 "Fast Flash" 0 "Slow Flash" ;
VAL_ 2566835198 FlashMalfuncIndicatorLamp 3 "Unavailable / Do Not Flash" 2 "Reserved" 1 "Fast Flash" 0 "Slow Flash" ;
VAL_ 2566835198 FlashAmberWarningLamp 3 "Unavailable / Do Not Flash" 2 "Reserved" 1 "Fast Flash" 0 "Slow Flash" ;
VAL_ 2566835198 FailureModeIdentifier2 31 "Not available" 19 "Received network data in error" 18 "Below normal (moderately severe)" 17 "Below normal (least severe)" 16 "Above normal (moderately severe)" 15 "Above normal (least severe)" 14 "Special intstructions" 13 "Out of calibration" 12 "Bad intelligent device" 11 "Root cause not known" 10 "Abnormal rate of change" 9 "Abnormal update rate" 8 "Abnormal frequency" 7 "Mechanical system not responding" 6 "Current above normal" 5 "Current below normal" 4 "Voltage below normal" 3 "Voltage above normal" 2 "Data erratic" 1 "Below normal (most severe)" 0 "Above normal (most severe)" ;
VAL_ 2566837502 FlashRedStopLamp 3 "Unavailable / Do Not Flash" 2 "Reserved" 1 "Fast Flash" 0 "Slow Flash" ;
VAL_ 2566837502 FlashProtectLamp 3 "Unavailable / Do Not Flash" 2 "Reserved" 1 "Fast Flash" 0 "Slow Flash" ;
VAL_ 2566837502 FailureModeIdentifier5 31 "Not available" 19 "Received network data in error" 18 "Below normal (moderately severe)" 17 "Below normal (least severe)" 16 "Above normal (moderately severe)" 15 "Above normal (least severe)" 14 "Special intstructions" 13 "Out of calibration" 12 "Bad intelligent device" 11 "Root cause not known" 10 "Abnormal rate of change" 9 "Abnormal update rate" 8 "Abnormal frequency" 7 "Mechanical system not responding" 6 "Current above normal" 5 "Current below normal" 4 "Voltage below normal" 3 "Voltage above normal" 2 "Data erratic" 1 "Below normal (most severe)" 0 "Above normal (most severe)" ;
VAL_ 2566837502 FailureModeIdentifier4 31 "Not available" 19 "Received network data in error" 18 "Below normal (moderately severe)" 17 "Below normal (least severe)" 16 "Above normal (moderately severe)" 15 "Above normal (least severe)" 14 "Special intstructions" 13 "Out of calibration" 12 "Bad intelligent device" 11 "Root cause not known" 10 "Abnormal rate of change" 9 "Abnormal update rate" 8 "Abnormal frequency" 7 "Mechanical system not responding" 6 "Current above normal" 5 "Current below normal" 4 "Voltage below normal" 3 "Voltage above normal" 2 "Data erratic" 1 "Below normal (most severe)" 0 "Above normal (most severe)" ;
VAL_ 2566837502 FailureModeIdentifier3 31 "Not available" 19 "Received network data in error" 18 "Below normal (moderately severe)" 17 "Below normal (least severe)" 16 "Above normal (moderately severe)" 15 "Above normal (least severe)" 14 "Special intstructions" 13 "Out of calibration" 12 "Bad intelligent device" 11 "Root cause not known" 10 "Abnormal rate of change" 9 "Abnormal update rate" 8 "Abnormal frequency" 7 "Mechanical system not responding" 6 "Current above normal" 5 "Current below normal" 4 "Voltage below normal" 3 "Voltage above normal" 2 "Data erratic" 1 "Below normal (most severe)" 0 "Above normal (most severe)" ;
VAL_ 2566837502 FailureModeIdentifier1 31 "Not available" 19 "Received network data in error" 18 "Below normal (moderately severe)" 17 "Below normal (least severe)" 16 "Above normal (moderately severe)" 15 "Above normal (least severe)" 14 "Special intstructions" 13 "Out of calibration" 12 "Bad intelligent device" 11 "Root cause not known" 10 "Abnormal rate of change" 9 "Abnormal update rate" 8 "Abnormal frequency" 7 "Mechanical system not responding" 6 "Current above normal" 5 "Current below normal" 4 "Voltage below normal" 3 "Voltage above normal" 2 "Data erratic" 1 "Below normal (most severe)" 0 "Above normal (most severe)" ;
VAL_ 2566837502 MalfunctionIndicatorLampStatus 3 "Not available" 2 "Reserved" 1 "Lamp on" 0 "Lamp off" ;
VAL_ 2566837502 RedStopLampState 3 "Not available" 2 "Reserved" 1 "Lamp on" 0 "Lamp off" ;
VAL_ 2566837502 AmberWarningLampStatus 3 "Not available" 2 "Reserved" 1 "Lamp on" 0 "Lamp off" ;
VAL_ 2566837502 ProtectLampStatus 3 "Not available" 2 "Reserved" 1 "Lamp on" 0 "Lamp off" ;
VAL_ 2566837502 FlashMalfuncIndicatorLamp 3 "Unavailable / Do Not Flash" 2 "Reserved" 1 "Fast Flash" 0 "Slow Flash" ;
VAL_ 2566837502 FlashAmberWarningLamp 3 "Unavailable / Do Not Flash" 2 "Reserved" 1 "Fast Flash" 0 "Slow Flash" ;
VAL_ 2566837502 FailureModeIdentifier2 31 "Not available" 19 "Received network data in error" 18 "Below normal (moderately severe)" 17 "Below normal (least severe)" 16 "Above normal (moderately severe)" 15 "Above normal (least severe)" 14 "Special intstructions" 13 "Out of calibration" 12 "Bad intelligent device" 11 "Root cause not known" 10 "Abnormal rate of change" 9 "Abnormal update rate" 8 "Abnormal frequency" 7 "Mechanical system not responding" 6 "Current above normal" 5 "Current below normal" 4 "Voltage below normal" 3 "Voltage above normal" 2 "Data erratic" 1 "Below normal (most severe)" 0 "Above normal (most severe)" ;
VAL_ 2566834942 FailureModeIdentifier5 31 "Not available" 19 "Received network data in error" 18 "Below normal (moderately severe)" 17 "Below normal (least severe)" 16 "Above normal (moderately severe)" 15 "Above normal (least severe)" 14 "Special intstructions" 13 "Out of calibration" 12 "Bad intelligent device" 11 "Root cause not known" 10 "Abnormal rate of change" 9 "Abnormal update rate" 8 "Abnormal frequency" 7 "Mechanical system not responding" 6 "Current above normal" 5 "Current below normal" 4 "Voltage below normal" 3 "Voltage above normal" 2 "Data erratic" 1 "Below normal (most severe)" 0 "Above normal (most severe)" ;
VAL_ 2566834942 FailureModeIdentifier4 31 "Not available" 19 "Received network data in error" 18 "Below normal (moderately severe)" 17 "Below normal (least severe)" 16 "Above normal (moderately severe)" 15 "Above normal (least severe)" 14 "Special intstructions" 13 "Out of calibration" 12 "Bad intelligent device" 11 "Root cause not known" 10 "Abnormal rate of change" 9 "Abnormal update rate" 8 "Abnormal frequency" 7 "Mechanical system not responding" 6 "Current above normal" 5 "Current below normal" 4 "Voltage below normal" 3 "Voltage above normal" 2 "Data erratic" 1 "Below normal (most severe)" 0 "Above normal (most severe)" ;
VAL_ 2566834942 FailureModeIdentifier3 31 "Not available" 19 "Received network data in error" 18 "Below normal (moderately severe)" 17 "Below normal (least severe)" 16 "Above normal (moderately severe)" 15 "Above normal (least severe)" 14 "Special intstructions" 13 "Out of calibration" 12 "Bad intelligent device" 11 "Root cause not known" 10 "Abnormal rate of change" 9 "Abnormal update rate" 8 "Abnormal frequency" 7 "Mechanical system not responding" 6 "Current above normal" 5 "Current below normal" 4 "Voltage below normal" 3 "Voltage above normal" 2 "Data erratic" 1 "Below normal (most severe)" 0 "Above normal (most severe)" ;
VAL_ 2566834942 FlashRedStopLamp 3 "Unavailable / Do Not Flash" 2 "Reserved" 1 "Fast Flash" 0 "Slow Flash" ;
VAL_ 2566834942 FlashProtectLamp 3 "Unavailable / Do Not Flash" 2 "Reserved" 1 "Fast Flash" 0 "Slow Flash" ;
VAL_ 2566834942 FlashMalfuncIndicatorLamp 3 "Unavailable / Do Not Flash" 2 "Reserved" 1 "Fast Flash" 0 "Slow Flash" ;
VAL_ 2566834942 FlashAmberWarningLamp 3 "Unavailable / Do Not Flash" 2 "Reserved" 1 "Fast Flash" 0 "Slow Flash" ;
VAL_ 2566834942 MalfunctionIndicatorLampStatus 3 "Not available" 2 "Reserved" 1 "Lamp on" 0 "Lamp off" ;
VAL_ 2566834942 AmberWarningLampStatus 3 "Not available" 2 "Reserved" 1 "Lamp on" 0 "Lamp off" ;
VAL_ 2566834942 FailureModeIdentifier1 31 "Not available" 19 "Received network data in error" 18 "Below normal (moderately severe)" 17 "Below normal (least severe)" 16 "Above normal (moderately severe)" 15 "Above normal (least severe)" 14 "Special intstructions" 13 "Out of calibration" 12 "Bad intelligent device" 11 "Root cause not known" 10 "Abnormal rate of change" 9 "Abnormal update rate" 8 "Abnormal frequency" 7 "Mechanical system not responding" 6 "Current above normal" 5 "Current below normal" 4 "Voltage below normal" 3 "Voltage above normal" 2 "Data erratic" 1 "Below normal (most severe)" 0 "Above normal (most severe)" ;
VAL_ 2566834942 RedStopLampState 3 "Not available" 2 "Reserved" 1 "Lamp on" 0 "Lamp off" ;
VAL_ 2566834942 ProtectLampStatus 3 "Not available" 2 "Reserved" 1 "Lamp on" 0 "Lamp off" ;
VAL_ 2566834942 FailureModeIdentifier2 31 "Not available" 19 "Received network data in error" 18 "Below normal (moderately severe)" 17 "Below normal (least severe)" 16 "Above normal (moderately severe)" 15 "Above normal (least severe)" 14 "Special intstructions" 13 "Out of calibration" 12 "Bad intelligent device" 11 "Root cause not known" 10 "Abnormal rate of change" 9 "Abnormal update rate" 8 "Abnormal frequency" 7 "Mechanical system not responding" 6 "Current above normal" 5 "Current below normal" 4 "Voltage below normal" 3 "Voltage above normal" 2 "Data erratic" 1 "Below normal (most severe)" 0 "Above normal (most severe)" ;
VAL_ 2565799678 IndustryGroup 7 "Reserve for SAE" 5 "IndustrialProcessCtrlStationary" 4 "Marine" 3 "Construction" 2 "Agricultural and Forestry" 1 "On-Highway" 0 "Global" ;
VAL_ 2565668606 PGNumber 255 "NotAvailable" ;
VAL_ 2565668606 ControlByte 24 "EAbort" 23 "EEoMACK" 22 "EDPO" 21 "ECTS" 20 "ERTS" 3 "CannotRespond" 2 "AccessDenied" 1 "NACK" 0 "ACK" 255 "Abort" 32 "BAM" 19 "EoMA" 17 "CTS" 16 "RTS" ;
VAL_ 2563374846 UseTransferMode 3 "NA" 2 "Undefined" 1 "Yes" 0 "No" ;
VAL_ 2565406462 ControlByte 24 "EAbort" 23 "EEoMACK" 22 "EDPO" 21 "ECTS" 20 "ERTS" 3 "CannotRespond" 2 "AccessDenied" 1 "NACK" 0 "ACK" 255 "Abort" 32 "BAM" 19 "EoMA" 17 "CTS" 16 "RTS" ;
